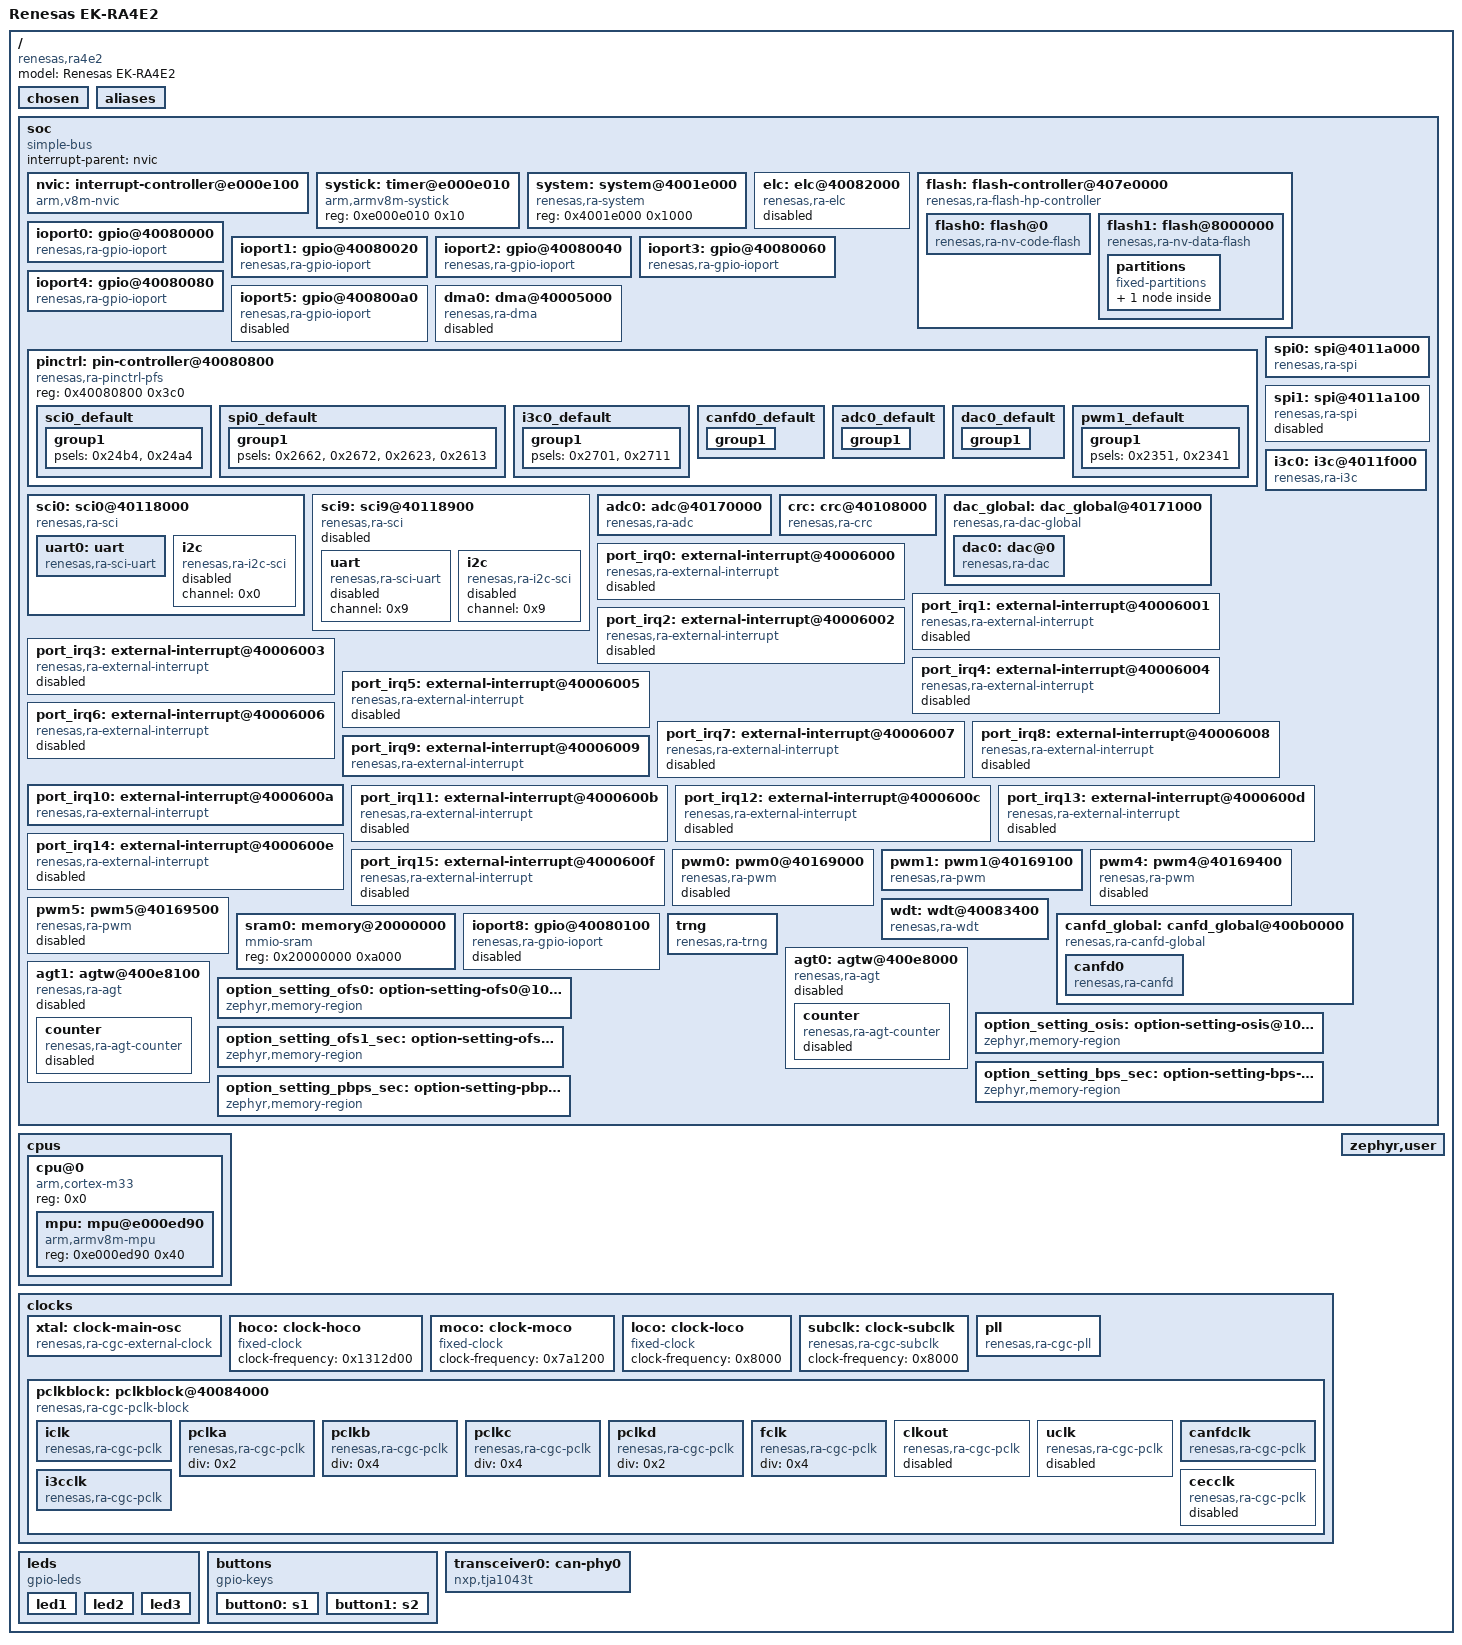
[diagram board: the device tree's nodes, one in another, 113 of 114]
/dts-v1/;

/* node '/' defined in zephyr/dts/common/skeleton.dtsi:9 */
/ {
	#address-cells = < 0x1 >;     /* in zephyr/dts/common/skeleton.dtsi:10 */
	#size-cells = < 0x1 >;        /* in zephyr/dts/common/skeleton.dtsi:11 */
	model = "Renesas EK-RA4E2";   /* in zephyr/boards/renesas/ek_ra4e2/ek_ra4e2.dts:15 */
	compatible = "renesas,ra4e2",
	             "renesas,ra";    /* in zephyr/boards/renesas/ek_ra4e2/ek_ra4e2.dts:16 */

	/* node '/chosen' defined in zephyr/dts/common/skeleton.dtsi:13 */
	chosen {
		zephyr,sram = &sram0;              /* in zephyr/boards/renesas/ek_ra4e2/ek_ra4e2.dts:19 */
		zephyr,flash-controller = &flash1; /* in zephyr/boards/renesas/ek_ra4e2/ek_ra4e2.dts:20 */
		zephyr,flash = &flash0;            /* in zephyr/boards/renesas/ek_ra4e2/ek_ra4e2.dts:21 */
		zephyr,console = &uart0;           /* in zephyr/boards/renesas/ek_ra4e2/ek_ra4e2.dts:22 */
		zephyr,shell-uart = &uart0;        /* in zephyr/boards/renesas/ek_ra4e2/ek_ra4e2.dts:23 */
		zephyr,canbus = &canfd0;           /* in zephyr/boards/renesas/ek_ra4e2/ek_ra4e2.dts:24 */
		zephyr,entropy = &trng;            /* in zephyr/boards/renesas/ek_ra4e2/ek_ra4e2.dts:25 */
		zephyr,crc = &crc;                 /* in zephyr/boards/renesas/ek_ra4e2/ek_ra4e2.dts:26 */
	};

	/* node '/aliases' defined in zephyr/dts/common/skeleton.dtsi:15 */
	aliases {
		led0 = &led1;     /* in zephyr/boards/renesas/ek_ra4e2/ek_ra4e2.dts:65 */
		sw0 = &button0;   /* in zephyr/boards/renesas/ek_ra4e2/ek_ra4e2.dts:66 */
		sw1 = &button1;   /* in zephyr/boards/renesas/ek_ra4e2/ek_ra4e2.dts:67 */
		watchdog0 = &wdt; /* in zephyr/boards/renesas/ek_ra4e2/ek_ra4e2.dts:68 */
	};

	/* node '/soc' defined in zephyr/dts/arm/armv8-m.dtsi:6 */
	soc {
		#address-cells = < 0x1 >;     /* in zephyr/dts/arm/armv8-m.dtsi:7 */
		#size-cells = < 0x1 >;        /* in zephyr/dts/arm/armv8-m.dtsi:8 */
		compatible = "simple-bus";    /* in zephyr/dts/arm/armv8-m.dtsi:9 */
		ranges;                       /* in zephyr/dts/arm/armv8-m.dtsi:11 */
		interrupt-parent = < &nvic >; /* in zephyr/dts/arm/renesas/ra/ra4/ra4-cm33-common.dtsi:33 */

		/* node '/soc/interrupt-controller@e000e100' defined in zephyr/dts/arm/armv8-m.dtsi:13 */
		nvic: interrupt-controller@e000e100 {
			#address-cells = < 0x1 >;            /* in zephyr/dts/arm/armv8-m.dtsi:14 */
			compatible = "arm,v8m-nvic";         /* in zephyr/dts/arm/armv8-m.dtsi:15 */
			reg = < 0xe000e100 0xc00 >;          /* in zephyr/dts/arm/armv8-m.dtsi:16 */
			interrupt-controller;                /* in zephyr/dts/arm/armv8-m.dtsi:17 */
			#interrupt-cells = < 0x2 >;          /* in zephyr/dts/arm/armv8-m.dtsi:18 */
			arm,num-irq-priority-bits = < 0x4 >; /* in zephyr/dts/arm/renesas/ra/ra4/ra4-cm33-common.dtsi:579 */
			phandle = < 0x1 >;                   /* in zephyr/dts/arm/renesas/ra/ra4/ra4-cm33-common.dtsi:33 */
		};

		/* node '/soc/timer@e000e010' defined in zephyr/dts/arm/armv8-m.dtsi:21 */
		systick: timer@e000e010 {
			compatible = "arm,armv8m-systick"; /* in zephyr/dts/arm/armv8-m.dtsi:22 */
			reg = < 0xe000e010 0x10 >;         /* in zephyr/dts/arm/armv8-m.dtsi:23 */
		};

		/* node '/soc/system@4001e000' defined in zephyr/dts/arm/renesas/ra/ra4/ra4-cm33-common.dtsi:35 */
		system: system@4001e000 {
			compatible = "renesas,ra-system"; /* in zephyr/dts/arm/renesas/ra/ra4/ra4-cm33-common.dtsi:36 */
			reg = < 0x4001e000 0x1000 >;      /* in zephyr/dts/arm/renesas/ra/ra4/ra4-cm33-common.dtsi:37 */
			status = "okay";                  /* in zephyr/dts/arm/renesas/ra/ra4/ra4-cm33-common.dtsi:38 */
		};

		/* node '/soc/elc@40082000' defined in zephyr/dts/arm/renesas/ra/ra4/ra4-cm33-common.dtsi:41 */
		elc: elc@40082000 {
			compatible = "renesas,ra-elc"; /* in zephyr/dts/arm/renesas/ra/ra4/ra4-cm33-common.dtsi:42 */
			reg = < 0x40082000 0x70 >;     /* in zephyr/dts/arm/renesas/ra/ra4/ra4-cm33-common.dtsi:43 */
			#renesas-elc-cells = < 0x2 >;  /* in zephyr/dts/arm/renesas/ra/ra4/ra4-cm33-common.dtsi:44 */
			clocks = < &pclkb 0x2 0xe >;   /* in zephyr/dts/arm/renesas/ra/ra4/ra4-cm33-common.dtsi:45 */
			status = "disabled";           /* in zephyr/dts/arm/renesas/ra/ra4/ra4-cm33-common.dtsi:46 */
		};

		/* node '/soc/flash-controller@407e0000' defined in zephyr/dts/arm/renesas/ra/ra4/ra4-cm33-common.dtsi:49 */
		flash: flash-controller@407e0000 {
			compatible = "renesas,ra-flash-hp-controller"; /* in zephyr/dts/arm/renesas/ra/ra4/ra4-cm33-common.dtsi:50 */
			reg = < 0x407e0000 0x10000 >;                  /* in zephyr/dts/arm/renesas/ra/ra4/ra4-cm33-common.dtsi:51 */
			#address-cells = < 0x1 >;                      /* in zephyr/dts/arm/renesas/ra/ra4/ra4-cm33-common.dtsi:52 */
			#size-cells = < 0x1 >;                         /* in zephyr/dts/arm/renesas/ra/ra4/ra4-cm33-common.dtsi:53 */
			interrupts = < 0x31 0x1 >,
			             < 0x32 0x1 >;                     /* in zephyr/dts/arm/renesas/ra/ra4/ra4-cm33-common.dtsi:54 */
			interrupt-names = "frdyi",
			                  "fiferr";                    /* in zephyr/dts/arm/renesas/ra/ra4/ra4-cm33-common.dtsi:55 */
			flash-hardware-version = < 0x28 >;             /* in zephyr/dts/arm/renesas/ra/ra4/r7fa4e2b93cfm.dtsi:43 */
			#erase-block-cells = < 0x2 >;                  /* in zephyr/dts/arm/renesas/ra/ra4/r7fa4e2b93cfm.dtsi:44 */
			phandle = < 0x3 >;                             /* in zephyr/dts/arm/renesas/ra/ra4/r7fa4e2b93cfm.dtsi:51 */

			/* node '/soc/flash-controller@407e0000/flash@0' defined in zephyr/dts/arm/renesas/ra/ra4/r7fa4e2b93cfm.dtsi:46 */
			flash0: flash@0 {
				compatible = "renesas,ra-nv-code-flash"; /* in zephyr/dts/arm/renesas/ra/ra4/r7fa4e2b93cfm.dtsi:47 */
				reg = < 0x0 0x20000 >;                   /* in zephyr/dts/arm/renesas/ra/ra4/r7fa4e2b93cfm.dtsi:48 */
				write-block-size = < 0x80 >;             /* in zephyr/dts/arm/renesas/ra/ra4/r7fa4e2b93cfm.dtsi:49 */
				erase-block-size = < 0x8000 >;           /* in zephyr/dts/arm/renesas/ra/ra4/r7fa4e2b93cfm.dtsi:50 */
				erase-blocks = < &flash 0x8 0x2000 >,
				               < &flash 0x2 0x8000 >;    /* in zephyr/dts/arm/renesas/ra/ra4/r7fa4e2b93cfm.dtsi:51 */
				programming-enable;                      /* in zephyr/dts/arm/renesas/ra/ra4/r7fa4e2b93cfm.dtsi:52 */
			};

			/* node '/soc/flash-controller@407e0000/flash@8000000' defined in zephyr/dts/arm/renesas/ra/ra4/r7fa4e2b93cfm.dtsi:55 */
			flash1: flash@8000000 {
				compatible = "renesas,ra-nv-data-flash"; /* in zephyr/dts/arm/renesas/ra/ra4/r7fa4e2b93cfm.dtsi:56 */
				reg = < 0x8000000 0x1000 >;              /* in zephyr/dts/arm/renesas/ra/ra4/r7fa4e2b93cfm.dtsi:57 */
				write-block-size = < 0x4 >;              /* in zephyr/dts/arm/renesas/ra/ra4/r7fa4e2b93cfm.dtsi:58 */
				erase-block-size = < 0x40 >;             /* in zephyr/dts/arm/renesas/ra/ra4/r7fa4e2b93cfm.dtsi:59 */
				programming-enable;                      /* in zephyr/dts/arm/renesas/ra/ra4/r7fa4e2b93cfm.dtsi:60 */
				erase-value-undefined;                   /* in zephyr/dts/arm/renesas/ra/ra4/r7fa4e2b93cfm.dtsi:61 */

				/* node '/soc/flash-controller@407e0000/flash@8000000/partitions' defined in zephyr/boards/renesas/ek_ra4e2/ek_ra4e2.dts:209 */
				partitions {
					compatible = "fixed-partitions"; /* in zephyr/boards/renesas/ek_ra4e2/ek_ra4e2.dts:210 */
					#address-cells = < 0x1 >;        /* in zephyr/boards/renesas/ek_ra4e2/ek_ra4e2.dts:211 */
					#size-cells = < 0x1 >;           /* in zephyr/boards/renesas/ek_ra4e2/ek_ra4e2.dts:212 */

					/* node '/soc/flash-controller@407e0000/flash@8000000/partitions/partition@0' defined in zephyr/boards/renesas/ek_ra4e2/ek_ra4e2.dts:214 */
					storage_partition: partition@0 {
						label = "storage";    /* in zephyr/boards/renesas/ek_ra4e2/ek_ra4e2.dts:215 */
						reg = < 0x0 0x1000 >; /* in zephyr/boards/renesas/ek_ra4e2/ek_ra4e2.dts:216 */
					};
				};
			};
		};

		/* node '/soc/gpio@40080000' defined in zephyr/dts/arm/renesas/ra/ra4/ra4-cm33-common.dtsi:58 */
		ioport0: gpio@40080000 {
			compatible = "renesas,ra-gpio-ioport";                                                                       /* in zephyr/dts/arm/renesas/ra/ra4/ra4-cm33-common.dtsi:59 */
			reg = < 0x40080000 0x20 >;                                                                                   /* in zephyr/dts/arm/renesas/ra/ra4/ra4-cm33-common.dtsi:60 */
			port = < 0x0 >;                                                                                              /* in zephyr/dts/arm/renesas/ra/ra4/ra4-cm33-common.dtsi:61 */
			gpio-controller;                                                                                             /* in zephyr/dts/arm/renesas/ra/ra4/ra4-cm33-common.dtsi:62 */
			#gpio-cells = < 0x2 >;                                                                                       /* in zephyr/dts/arm/renesas/ra/ra4/ra4-cm33-common.dtsi:63 */
			ngpios = < 0x10 >;                                                                                           /* in zephyr/dts/arm/renesas/ra/ra4/ra4-cm33-common.dtsi:64 */
			port-irqs = < &port_irq6 &port_irq7 &port_irq8 &port_irq9 &port_irq10 &port_irq11 &port_irq12 &port_irq13 >; /* in zephyr/dts/arm/renesas/ra/ra4/r7fa4e2b93cfm.dtsi:295 */
			port-irq-names = "port-irq6",
			                 "port-irq7",
			                 "port-irq8",
			                 "port-irq9",
			                 "port-irq10",
			                 "port-irq11",
			                 "port-irq12",
			                 "port-irq13";                                                                               /* in zephyr/dts/arm/renesas/ra/ra4/r7fa4e2b93cfm.dtsi:298 */
			port-irq6-pins = < 0x0 >;                                                                                    /* in zephyr/dts/arm/renesas/ra/ra4/r7fa4e2b93cfm.dtsi:306 */
			port-irq7-pins = < 0x1 >;                                                                                    /* in zephyr/dts/arm/renesas/ra/ra4/r7fa4e2b93cfm.dtsi:307 */
			port-irq8-pins = < 0x2 >;                                                                                    /* in zephyr/dts/arm/renesas/ra/ra4/r7fa4e2b93cfm.dtsi:308 */
			port-irq9-pins = < 0x4 >;                                                                                    /* in zephyr/dts/arm/renesas/ra/ra4/r7fa4e2b93cfm.dtsi:309 */
			port-irq10-pins = < 0x5 >;                                                                                   /* in zephyr/dts/arm/renesas/ra/ra4/r7fa4e2b93cfm.dtsi:310 */
			port-irq11-pins = < 0x6 >;                                                                                   /* in zephyr/dts/arm/renesas/ra/ra4/r7fa4e2b93cfm.dtsi:311 */
			port-irq12-pins = < 0x8 >;                                                                                   /* in zephyr/dts/arm/renesas/ra/ra4/r7fa4e2b93cfm.dtsi:312 */
			port-irq13-pins = < 0xf >;                                                                                   /* in zephyr/dts/arm/renesas/ra/ra4/r7fa4e2b93cfm.dtsi:313 */
			status = "okay";                                                                                             /* in zephyr/boards/renesas/ek_ra4e2/ek_ra4e2.dts:114 */
			phandle = < 0x24 >;                                                                                          /* in zephyr/boards/renesas/ek_ra4e2/ek_ra4e2.dts:52 */
		};

		/* node '/soc/gpio@40080020' defined in zephyr/dts/arm/renesas/ra/ra4/ra4-cm33-common.dtsi:68 */
		ioport1: gpio@40080020 {
			compatible = "renesas,ra-gpio-ioport";                                  /* in zephyr/dts/arm/renesas/ra/ra4/ra4-cm33-common.dtsi:69 */
			reg = < 0x40080020 0x20 >;                                              /* in zephyr/dts/arm/renesas/ra/ra4/ra4-cm33-common.dtsi:70 */
			port = < 0x1 >;                                                         /* in zephyr/dts/arm/renesas/ra/ra4/ra4-cm33-common.dtsi:71 */
			gpio-controller;                                                        /* in zephyr/dts/arm/renesas/ra/ra4/ra4-cm33-common.dtsi:72 */
			#gpio-cells = < 0x2 >;                                                  /* in zephyr/dts/arm/renesas/ra/ra4/ra4-cm33-common.dtsi:73 */
			ngpios = < 0x10 >;                                                      /* in zephyr/dts/arm/renesas/ra/ra4/ra4-cm33-common.dtsi:74 */
			port-irqs = < &port_irq0 &port_irq1 &port_irq2 &port_irq3 &port_irq4 >; /* in zephyr/dts/arm/renesas/ra/ra4/r7fa4e2b93cfm.dtsi:317 */
			port-irq-names = "port-irq0",
			                 "port-irq1",
			                 "port-irq2",
			                 "port-irq3",
			                 "port-irq4";                                           /* in zephyr/dts/arm/renesas/ra/ra4/r7fa4e2b93cfm.dtsi:319 */
			port-irq0-pins = < 0x5 >;                                               /* in zephyr/dts/arm/renesas/ra/ra4/r7fa4e2b93cfm.dtsi:324 */
			port-irq1-pins = < 0x1 0x4 >;                                           /* in zephyr/dts/arm/renesas/ra/ra4/r7fa4e2b93cfm.dtsi:325 */
			port-irq2-pins = < 0x0 >;                                               /* in zephyr/dts/arm/renesas/ra/ra4/r7fa4e2b93cfm.dtsi:326 */
			port-irq3-pins = < 0xa >;                                               /* in zephyr/dts/arm/renesas/ra/ra4/r7fa4e2b93cfm.dtsi:327 */
			port-irq4-pins = < 0xb >;                                               /* in zephyr/dts/arm/renesas/ra/ra4/r7fa4e2b93cfm.dtsi:328 */
			status = "okay";                                                        /* in zephyr/boards/renesas/ek_ra4e2/ek_ra4e2.dts:118 */
			phandle = < 0x23 >;                                                     /* in zephyr/boards/renesas/ek_ra4e2/ek_ra4e2.dts:38 */
		};

		/* node '/soc/gpio@40080040' defined in zephyr/dts/arm/renesas/ra/ra4/ra4-cm33-common.dtsi:78 */
		ioport2: gpio@40080040 {
			compatible = "renesas,ra-gpio-ioport";                       /* in zephyr/dts/arm/renesas/ra/ra4/ra4-cm33-common.dtsi:79 */
			reg = < 0x40080040 0x20 >;                                   /* in zephyr/dts/arm/renesas/ra/ra4/ra4-cm33-common.dtsi:80 */
			port = < 0x2 >;                                              /* in zephyr/dts/arm/renesas/ra/ra4/ra4-cm33-common.dtsi:81 */
			gpio-controller;                                             /* in zephyr/dts/arm/renesas/ra/ra4/ra4-cm33-common.dtsi:82 */
			#gpio-cells = < 0x2 >;                                       /* in zephyr/dts/arm/renesas/ra/ra4/ra4-cm33-common.dtsi:83 */
			ngpios = < 0x10 >;                                           /* in zephyr/dts/arm/renesas/ra/ra4/ra4-cm33-common.dtsi:84 */
			port-irqs = < &port_irq0 &port_irq1 &port_irq2 &port_irq3 >; /* in zephyr/dts/arm/renesas/ra/ra4/r7fa4e2b93cfm.dtsi:332 */
			port-irq-names = "port-irq0",
			                 "port-irq1",
			                 "port-irq2",
			                 "port-irq3";                                /* in zephyr/dts/arm/renesas/ra/ra4/r7fa4e2b93cfm.dtsi:334 */
			port-irq0-pins = < 0x6 >;                                    /* in zephyr/dts/arm/renesas/ra/ra4/r7fa4e2b93cfm.dtsi:338 */
			port-irq1-pins = < 0x5 >;                                    /* in zephyr/dts/arm/renesas/ra/ra4/r7fa4e2b93cfm.dtsi:339 */
			port-irq2-pins = < 0xd >;                                    /* in zephyr/dts/arm/renesas/ra/ra4/r7fa4e2b93cfm.dtsi:340 */
			port-irq3-pins = < 0xc >;                                    /* in zephyr/dts/arm/renesas/ra/ra4/r7fa4e2b93cfm.dtsi:341 */
			status = "okay";                                             /* in zephyr/boards/renesas/ek_ra4e2/ek_ra4e2.dts:122 */
			phandle = < 0x22 >;                                          /* in zephyr/boards/renesas/ek_ra4e2/ek_ra4e2.dts:33 */
		};

		/* node '/soc/gpio@40080060' defined in zephyr/dts/arm/renesas/ra/ra4/ra4-cm33-common.dtsi:88 */
		ioport3: gpio@40080060 {
			compatible = "renesas,ra-gpio-ioport";            /* in zephyr/dts/arm/renesas/ra/ra4/ra4-cm33-common.dtsi:89 */
			reg = < 0x40080060 0x20 >;                        /* in zephyr/dts/arm/renesas/ra/ra4/ra4-cm33-common.dtsi:90 */
			port = < 0x3 >;                                   /* in zephyr/dts/arm/renesas/ra/ra4/ra4-cm33-common.dtsi:91 */
			gpio-controller;                                  /* in zephyr/dts/arm/renesas/ra/ra4/ra4-cm33-common.dtsi:92 */
			#gpio-cells = < 0x2 >;                            /* in zephyr/dts/arm/renesas/ra/ra4/ra4-cm33-common.dtsi:93 */
			ngpios = < 0x10 >;                                /* in zephyr/dts/arm/renesas/ra/ra4/ra4-cm33-common.dtsi:94 */
			port-irqs = < &port_irq5 &port_irq6 &port_irq9 >; /* in zephyr/dts/arm/renesas/ra/ra4/r7fa4e2b93cfm.dtsi:345 */
			port-irq-names = "port-irq5",
			                 "port-irq6",
			                 "port-irq9";                     /* in zephyr/dts/arm/renesas/ra/ra4/r7fa4e2b93cfm.dtsi:346 */
			port-irq5-pins = < 0x2 >;                         /* in zephyr/dts/arm/renesas/ra/ra4/r7fa4e2b93cfm.dtsi:349 */
			port-irq6-pins = < 0x1 >;                         /* in zephyr/dts/arm/renesas/ra/ra4/r7fa4e2b93cfm.dtsi:350 */
			port-irq9-pins = < 0x4 >;                         /* in zephyr/dts/arm/renesas/ra/ra4/r7fa4e2b93cfm.dtsi:351 */
			status = "okay";                                  /* in zephyr/boards/renesas/ek_ra4e2/ek_ra4e2.dts:182 */
			phandle = < 0x25 >;                               /* in zephyr/boards/renesas/ek_ra4e2/ek_ra4e2.dts:58 */
		};

		/* node '/soc/gpio@40080080' defined in zephyr/dts/arm/renesas/ra/ra4/ra4-cm33-common.dtsi:98 */
		ioport4: gpio@40080080 {
			compatible = "renesas,ra-gpio-ioport";                                              /* in zephyr/dts/arm/renesas/ra/ra4/ra4-cm33-common.dtsi:99 */
			reg = < 0x40080080 0x20 >;                                                          /* in zephyr/dts/arm/renesas/ra/ra4/ra4-cm33-common.dtsi:100 */
			port = < 0x4 >;                                                                     /* in zephyr/dts/arm/renesas/ra/ra4/ra4-cm33-common.dtsi:101 */
			gpio-controller;                                                                    /* in zephyr/dts/arm/renesas/ra/ra4/ra4-cm33-common.dtsi:102 */
			#gpio-cells = < 0x2 >;                                                              /* in zephyr/dts/arm/renesas/ra/ra4/ra4-cm33-common.dtsi:103 */
			ngpios = < 0x10 >;                                                                  /* in zephyr/dts/arm/renesas/ra/ra4/ra4-cm33-common.dtsi:104 */
			port-irqs = < &port_irq0 &port_irq4 &port_irq5 &port_irq6 &port_irq7 &port_irq14 >; /* in zephyr/dts/arm/renesas/ra/ra4/r7fa4e2b93cfm.dtsi:355 */
			port-irq-names = "port-irq0",
			                 "port-irq4",
			                 "port-irq5",
			                 "port-irq6",
			                 "port-irq7",
			                 "port-irq14";                                                      /* in zephyr/dts/arm/renesas/ra/ra4/r7fa4e2b93cfm.dtsi:357 */
			port-irq0-pins = < 0x0 >;                                                           /* in zephyr/dts/arm/renesas/ra/ra4/r7fa4e2b93cfm.dtsi:363 */
			port-irq4-pins = < 0x2 0xb >;                                                       /* in zephyr/dts/arm/renesas/ra/ra4/r7fa4e2b93cfm.dtsi:364 */
			port-irq5-pins = < 0x1 0xa >;                                                       /* in zephyr/dts/arm/renesas/ra/ra4/r7fa4e2b93cfm.dtsi:365 */
			port-irq6-pins = < 0x9 >;                                                           /* in zephyr/dts/arm/renesas/ra/ra4/r7fa4e2b93cfm.dtsi:366 */
			port-irq7-pins = < 0x8 >;                                                           /* in zephyr/dts/arm/renesas/ra/ra4/r7fa4e2b93cfm.dtsi:367 */
			port-irq14-pins = < 0x3 >;                                                          /* in zephyr/dts/arm/renesas/ra/ra4/r7fa4e2b93cfm.dtsi:368 */
			status = "okay";                                                                    /* in zephyr/boards/renesas/ek_ra4e2/ek_ra4e2.dts:142 */
			phandle = < 0x26 >;                                                                 /* in zephyr/boards/renesas/ek_ra4e2/ek_ra4e2.dts:73 */
		};

		/* node '/soc/gpio@400800a0' defined in zephyr/dts/arm/renesas/ra/ra4/ra4-cm33-common.dtsi:109 */
		ioport5: gpio@400800a0 {
			compatible = "renesas,ra-gpio-ioport"; /* in zephyr/dts/arm/renesas/ra/ra4/ra4-cm33-common.dtsi:110 */
			reg = < 0x400800a0 0x20 >;             /* in zephyr/dts/arm/renesas/ra/ra4/ra4-cm33-common.dtsi:111 */
			port = < 0x5 >;                        /* in zephyr/dts/arm/renesas/ra/ra4/ra4-cm33-common.dtsi:112 */
			gpio-controller;                       /* in zephyr/dts/arm/renesas/ra/ra4/ra4-cm33-common.dtsi:113 */
			#gpio-cells = < 0x2 >;                 /* in zephyr/dts/arm/renesas/ra/ra4/ra4-cm33-common.dtsi:114 */
			ngpios = < 0x10 >;                     /* in zephyr/dts/arm/renesas/ra/ra4/ra4-cm33-common.dtsi:115 */
			status = "disabled";                   /* in zephyr/dts/arm/renesas/ra/ra4/ra4-cm33-common.dtsi:116 */
		};

		/* node '/soc/dma@40005000' defined in zephyr/dts/arm/renesas/ra/ra4/ra4-cm33-common.dtsi:119 */
		dma0: dma@40005000 {
			compatible = "renesas,ra-dma"; /* in zephyr/dts/arm/renesas/ra/ra4/ra4-cm33-common.dtsi:120 */
			reg = < 0x40005000 0x200 >,
			      < 0x40005200 0xa0 >;     /* in zephyr/dts/arm/renesas/ra/ra4/ra4-cm33-common.dtsi:121 */
			reg-names = "channel",
			            "common";          /* in zephyr/dts/arm/renesas/ra/ra4/ra4-cm33-common.dtsi:122 */
			clocks = < &iclk 0x0 0x16 >;   /* in zephyr/dts/arm/renesas/ra/ra4/ra4-cm33-common.dtsi:123 */
			dma-channels = < 0x8 >;        /* in zephyr/dts/arm/renesas/ra/ra4/ra4-cm33-common.dtsi:124 */
			#dma-cells = < 0x2 >;          /* in zephyr/dts/arm/renesas/ra/ra4/ra4-cm33-common.dtsi:125 */
			status = "disabled";           /* in zephyr/dts/arm/renesas/ra/ra4/ra4-cm33-common.dtsi:126 */
		};

		/* node '/soc/pin-controller@40080800' defined in zephyr/dts/arm/renesas/ra/ra4/ra4-cm33-common.dtsi:129 */
		pinctrl: pin-controller@40080800 {
			compatible = "renesas,ra-pinctrl-pfs"; /* in zephyr/dts/arm/renesas/ra/ra4/ra4-cm33-common.dtsi:130 */
			reg = < 0x40080800 0x3c0 >;            /* in zephyr/dts/arm/renesas/ra/ra4/ra4-cm33-common.dtsi:131 */
			status = "okay";                       /* in zephyr/dts/arm/renesas/ra/ra4/ra4-cm33-common.dtsi:132 */

			/* node '/soc/pin-controller@40080800/sci0_default' defined in zephyr/boards/renesas/ek_ra4e2/ek_ra4e2-pinctrl.dtsi:7 */
			sci0_default: sci0_default {
				phandle = < 0x15 >; /* in zephyr/boards/renesas/ek_ra4e2/ek_ra4e2.dts:103 */

				/* node '/soc/pin-controller@40080800/sci0_default/group1' defined in zephyr/boards/renesas/ek_ra4e2/ek_ra4e2-pinctrl.dtsi:8 */
				group1 {
					psels = < 0x24b4 >,
					        < 0x24a4 >; /* in zephyr/boards/renesas/ek_ra4e2/ek_ra4e2-pinctrl.dtsi:10 */
				};
			};

			/* node '/soc/pin-controller@40080800/spi0_default' defined in zephyr/boards/renesas/ek_ra4e2/ek_ra4e2-pinctrl.dtsi:15 */
			spi0_default: spi0_default {
				phandle = < 0x16 >; /* in zephyr/boards/renesas/ek_ra4e2/ek_ra4e2.dts:126 */

				/* node '/soc/pin-controller@40080800/spi0_default/group1' defined in zephyr/boards/renesas/ek_ra4e2/ek_ra4e2-pinctrl.dtsi:16 */
				group1 {
					psels = < 0x2662 >,
					        < 0x2672 >,
					        < 0x2623 >,
					        < 0x2613 >; /* in zephyr/boards/renesas/ek_ra4e2/ek_ra4e2-pinctrl.dtsi:18 */
				};
			};

			/* node '/soc/pin-controller@40080800/i3c0_default' defined in zephyr/boards/renesas/ek_ra4e2/ek_ra4e2-pinctrl.dtsi:25 */
			i3c0_default: i3c0_default {
				phandle = < 0x18 >; /* in zephyr/boards/renesas/ek_ra4e2/ek_ra4e2.dts:134 */

				/* node '/soc/pin-controller@40080800/i3c0_default/group1' defined in zephyr/boards/renesas/ek_ra4e2/ek_ra4e2-pinctrl.dtsi:26 */
				group1 {
					psels = < 0x2701 >,
					        < 0x2711 >; /* in zephyr/boards/renesas/ek_ra4e2/ek_ra4e2-pinctrl.dtsi:28 */
				};
			};

			/* node '/soc/pin-controller@40080800/canfd0_default' defined in zephyr/boards/renesas/ek_ra4e2/ek_ra4e2-pinctrl.dtsi:33 */
			canfd0_default: canfd0_default {
				phandle = < 0x1e >; /* in zephyr/boards/renesas/ek_ra4e2/ek_ra4e2.dts:161 */

				/* node '/soc/pin-controller@40080800/canfd0_default/group1' defined in zephyr/boards/renesas/ek_ra4e2/ek_ra4e2-pinctrl.dtsi:34 */
				group1 {
					psels = < 0x3024 >,
					        < 0x3014 >;      /* in zephyr/boards/renesas/ek_ra4e2/ek_ra4e2-pinctrl.dtsi:36 */
					drive-strength = "high"; /* in zephyr/boards/renesas/ek_ra4e2/ek_ra4e2-pinctrl.dtsi:38 */
				};
			};

			/* node '/soc/pin-controller@40080800/adc0_default' defined in zephyr/boards/renesas/ek_ra4e2/ek_ra4e2-pinctrl.dtsi:42 */
			adc0_default: adc0_default {
				phandle = < 0x19 >; /* in zephyr/boards/renesas/ek_ra4e2/ek_ra4e2.dts:171 */

				/* node '/soc/pin-controller@40080800/adc0_default/group1' defined in zephyr/boards/renesas/ek_ra4e2/ek_ra4e2-pinctrl.dtsi:43 */
				group1 {
					psels = < 0x2000 >;    /* in zephyr/boards/renesas/ek_ra4e2/ek_ra4e2-pinctrl.dtsi:45 */
					renesas,analog-enable; /* in zephyr/boards/renesas/ek_ra4e2/ek_ra4e2-pinctrl.dtsi:46 */
				};
			};

			/* node '/soc/pin-controller@40080800/dac0_default' defined in zephyr/boards/renesas/ek_ra4e2/ek_ra4e2-pinctrl.dtsi:50 */
			dac0_default: dac0_default {
				phandle = < 0x1a >; /* in zephyr/boards/renesas/ek_ra4e2/ek_ra4e2.dts:176 */

				/* node '/soc/pin-controller@40080800/dac0_default/group1' defined in zephyr/boards/renesas/ek_ra4e2/ek_ra4e2-pinctrl.dtsi:51 */
				group1 {
					psels = < 0x20e0 >;    /* in zephyr/boards/renesas/ek_ra4e2/ek_ra4e2-pinctrl.dtsi:53 */
					renesas,analog-enable; /* in zephyr/boards/renesas/ek_ra4e2/ek_ra4e2-pinctrl.dtsi:54 */
				};
			};

			/* node '/soc/pin-controller@40080800/pwm1_default' defined in zephyr/boards/renesas/ek_ra4e2/ek_ra4e2-pinctrl.dtsi:58 */
			pwm1_default: pwm1_default {
				phandle = < 0x1c >; /* in zephyr/boards/renesas/ek_ra4e2/ek_ra4e2.dts:196 */

				/* node '/soc/pin-controller@40080800/pwm1_default/group1' defined in zephyr/boards/renesas/ek_ra4e2/ek_ra4e2-pinctrl.dtsi:59 */
				group1 {
					psels = < 0x2351 >,
					        < 0x2341 >; /* in zephyr/boards/renesas/ek_ra4e2/ek_ra4e2-pinctrl.dtsi:61 */
				};
			};
		};

		/* node '/soc/sci0@40118000' defined in zephyr/dts/arm/renesas/ra/ra4/ra4-cm33-common.dtsi:135 */
		sci0: sci0@40118000 {
			compatible = "renesas,ra-sci"; /* in zephyr/dts/arm/renesas/ra/ra4/ra4-cm33-common.dtsi:136 */
			interrupts = < 0x0 0x1 >,
			             < 0x1 0x1 >,
			             < 0x2 0x1 >,
			             < 0x3 0x1 >;      /* in zephyr/dts/arm/renesas/ra/ra4/ra4-cm33-common.dtsi:137 */
			interrupt-names = "rxi",
			                  "txi",
			                  "tei",
			                  "eri";       /* in zephyr/dts/arm/renesas/ra/ra4/ra4-cm33-common.dtsi:138 */
			reg = < 0x40118000 0x100 >;    /* in zephyr/dts/arm/renesas/ra/ra4/ra4-cm33-common.dtsi:139 */
			clocks = < &pclka 0x1 0x1f >;  /* in zephyr/dts/arm/renesas/ra/ra4/ra4-cm33-common.dtsi:140 */
			pinctrl-0 = < &sci0_default >; /* in zephyr/boards/renesas/ek_ra4e2/ek_ra4e2.dts:103 */
			pinctrl-names = "default";     /* in zephyr/boards/renesas/ek_ra4e2/ek_ra4e2.dts:104 */
			status = "okay";               /* in zephyr/boards/renesas/ek_ra4e2/ek_ra4e2.dts:105 */

			/* node '/soc/sci0@40118000/uart' defined in zephyr/dts/arm/renesas/ra/ra4/ra4-cm33-common.dtsi:143 */
			uart0: uart {
				compatible = "renesas,ra-sci-uart"; /* in zephyr/dts/arm/renesas/ra/ra4/ra4-cm33-common.dtsi:144 */
				channel = < 0x0 >;                  /* in zephyr/dts/arm/renesas/ra/ra4/ra4-cm33-common.dtsi:145 */
				current-speed = < 0x1c200 >;        /* in zephyr/boards/renesas/ek_ra4e2/ek_ra4e2.dts:108 */
				status = "okay";                    /* in zephyr/boards/renesas/ek_ra4e2/ek_ra4e2.dts:109 */
			};

			/* node '/soc/sci0@40118000/i2c' defined in zephyr/dts/arm/renesas/ra/ra4/ra4-cm33-common.dtsi:149 */
			i2c {
				compatible = "renesas,ra-i2c-sci"; /* in zephyr/dts/arm/renesas/ra/ra4/ra4-cm33-common.dtsi:150 */
				#address-cells = < 0x1 >;          /* in zephyr/dts/arm/renesas/ra/ra4/ra4-cm33-common.dtsi:151 */
				#size-cells = < 0x0 >;             /* in zephyr/dts/arm/renesas/ra/ra4/ra4-cm33-common.dtsi:152 */
				channel = < 0x0 >;                 /* in zephyr/dts/arm/renesas/ra/ra4/ra4-cm33-common.dtsi:153 */
				status = "disabled";               /* in zephyr/dts/arm/renesas/ra/ra4/ra4-cm33-common.dtsi:154 */
			};
		};

		/* node '/soc/sci9@40118900' defined in zephyr/dts/arm/renesas/ra/ra4/ra4-cm33-common.dtsi:158 */
		sci9: sci9@40118900 {
			compatible = "renesas,ra-sci"; /* in zephyr/dts/arm/renesas/ra/ra4/ra4-cm33-common.dtsi:159 */
			interrupts = < 0x18 0x1 >,
			             < 0x19 0x1 >,
			             < 0x1a 0x1 >,
			             < 0x1b 0x1 >;     /* in zephyr/dts/arm/renesas/ra/ra4/ra4-cm33-common.dtsi:160 */
			interrupt-names = "rxi",
			                  "txi",
			                  "tei",
			                  "eri";       /* in zephyr/dts/arm/renesas/ra/ra4/ra4-cm33-common.dtsi:161 */
			reg = < 0x40118900 0x100 >;    /* in zephyr/dts/arm/renesas/ra/ra4/ra4-cm33-common.dtsi:162 */
			clocks = < &pclka 0x1 0x16 >;  /* in zephyr/dts/arm/renesas/ra/ra4/ra4-cm33-common.dtsi:163 */
			status = "disabled";           /* in zephyr/dts/arm/renesas/ra/ra4/ra4-cm33-common.dtsi:164 */

			/* node '/soc/sci9@40118900/uart' defined in zephyr/dts/arm/renesas/ra/ra4/ra4-cm33-common.dtsi:166 */
			uart {
				compatible = "renesas,ra-sci-uart"; /* in zephyr/dts/arm/renesas/ra/ra4/ra4-cm33-common.dtsi:167 */
				channel = < 0x9 >;                  /* in zephyr/dts/arm/renesas/ra/ra4/ra4-cm33-common.dtsi:168 */
				status = "disabled";                /* in zephyr/dts/arm/renesas/ra/ra4/ra4-cm33-common.dtsi:169 */
			};

			/* node '/soc/sci9@40118900/i2c' defined in zephyr/dts/arm/renesas/ra/ra4/ra4-cm33-common.dtsi:172 */
			i2c {
				compatible = "renesas,ra-i2c-sci"; /* in zephyr/dts/arm/renesas/ra/ra4/ra4-cm33-common.dtsi:173 */
				#address-cells = < 0x1 >;          /* in zephyr/dts/arm/renesas/ra/ra4/ra4-cm33-common.dtsi:174 */
				#size-cells = < 0x0 >;             /* in zephyr/dts/arm/renesas/ra/ra4/ra4-cm33-common.dtsi:175 */
				channel = < 0x9 >;                 /* in zephyr/dts/arm/renesas/ra/ra4/ra4-cm33-common.dtsi:176 */
				status = "disabled";               /* in zephyr/dts/arm/renesas/ra/ra4/ra4-cm33-common.dtsi:177 */
			};
		};

		/* node '/soc/spi@4011a000' defined in zephyr/dts/arm/renesas/ra/ra4/ra4-cm33-common.dtsi:181 */
		spi0: spi@4011a000 {
			compatible = "renesas,ra-spi"; /* in zephyr/dts/arm/renesas/ra/ra4/ra4-cm33-common.dtsi:182 */
			#address-cells = < 0x1 >;      /* in zephyr/dts/arm/renesas/ra/ra4/ra4-cm33-common.dtsi:183 */
			#size-cells = < 0x0 >;         /* in zephyr/dts/arm/renesas/ra/ra4/ra4-cm33-common.dtsi:184 */
			channel = < 0x0 >;             /* in zephyr/dts/arm/renesas/ra/ra4/ra4-cm33-common.dtsi:185 */
			interrupts = < 0x1c 0x1 >,
			             < 0x1d 0x1 >,
			             < 0x1e 0x1 >,
			             < 0x1f 0x1 >;     /* in zephyr/dts/arm/renesas/ra/ra4/ra4-cm33-common.dtsi:186 */
			interrupt-names = "rxi",
			                  "txi",
			                  "tei",
			                  "eri";       /* in zephyr/dts/arm/renesas/ra/ra4/ra4-cm33-common.dtsi:187 */
			reg = < 0x4011a000 0x100 >;    /* in zephyr/dts/arm/renesas/ra/ra4/ra4-cm33-common.dtsi:188 */
			pinctrl-0 = < &spi0_default >; /* in zephyr/boards/renesas/ek_ra4e2/ek_ra4e2.dts:126 */
			pinctrl-names = "default";     /* in zephyr/boards/renesas/ek_ra4e2/ek_ra4e2.dts:127 */
			status = "okay";               /* in zephyr/boards/renesas/ek_ra4e2/ek_ra4e2.dts:128 */
		};

		/* node '/soc/spi@4011a100' defined in zephyr/dts/arm/renesas/ra/ra4/ra4-cm33-common.dtsi:192 */
		spi1: spi@4011a100 {
			compatible = "renesas,ra-spi"; /* in zephyr/dts/arm/renesas/ra/ra4/ra4-cm33-common.dtsi:193 */
			#address-cells = < 0x1 >;      /* in zephyr/dts/arm/renesas/ra/ra4/ra4-cm33-common.dtsi:194 */
			#size-cells = < 0x0 >;         /* in zephyr/dts/arm/renesas/ra/ra4/ra4-cm33-common.dtsi:195 */
			channel = < 0x1 >;             /* in zephyr/dts/arm/renesas/ra/ra4/ra4-cm33-common.dtsi:196 */
			reg = < 0x4011a100 0x100 >;    /* in zephyr/dts/arm/renesas/ra/ra4/ra4-cm33-common.dtsi:197 */
			status = "disabled";           /* in zephyr/dts/arm/renesas/ra/ra4/ra4-cm33-common.dtsi:198 */
		};

		/* node '/soc/i3c@4011f000' defined in zephyr/dts/arm/renesas/ra/ra4/ra4-cm33-common.dtsi:201 */
		i3c0: i3c@4011f000 {
			compatible = "renesas,ra-i3c"; /* in zephyr/dts/arm/renesas/ra/ra4/ra4-cm33-common.dtsi:202 */
			#address-cells = < 0x3 >;      /* in zephyr/dts/arm/renesas/ra/ra4/ra4-cm33-common.dtsi:203 */
			#size-cells = < 0x0 >;         /* in zephyr/dts/arm/renesas/ra/ra4/ra4-cm33-common.dtsi:204 */
			reg = < 0x4011f000 0x3e8 >;    /* in zephyr/dts/arm/renesas/ra/ra4/ra4-cm33-common.dtsi:205 */
			channel = < 0x0 >;             /* in zephyr/dts/arm/renesas/ra/ra4/ra4-cm33-common.dtsi:206 */
			clocks = < &pclka 0x1 0x4 >,
			         < &i3cclk 0x0 0x0 >;  /* in zephyr/dts/arm/renesas/ra/ra4/ra4-cm33-common.dtsi:207 */
			clock-names = "pclk",
			              "tclk";          /* in zephyr/dts/arm/renesas/ra/ra4/ra4-cm33-common.dtsi:208 */
			i2c-scl-hz = < 0x61a80 >;      /* in zephyr/boards/renesas/ek_ra4e2/ek_ra4e2.dts:132 */
			i3c-scl-hz = < 0x3d0900 >;     /* in zephyr/boards/renesas/ek_ra4e2/ek_ra4e2.dts:133 */
			pinctrl-0 = < &i3c0_default >; /* in zephyr/boards/renesas/ek_ra4e2/ek_ra4e2.dts:134 */
			pinctrl-names = "default";     /* in zephyr/boards/renesas/ek_ra4e2/ek_ra4e2.dts:135 */
			interrupts = < 0x33 0x1 >,
			             < 0x34 0x1 >,
			             < 0x35 0x1 >,
			             < 0x36 0x1 >,
			             < 0x37 0x1 >,
			             < 0x38 0x1 >;     /* in zephyr/boards/renesas/ek_ra4e2/ek_ra4e2.dts:136 */
			interrupt-names = "resp",
			                  "rx",
			                  "tx",
			                  "rcv",
			                  "ibi",
			                  "eei";       /* in zephyr/boards/renesas/ek_ra4e2/ek_ra4e2.dts:137 */
			status = "okay";               /* in zephyr/boards/renesas/ek_ra4e2/ek_ra4e2.dts:138 */
		};

		/* node '/soc/adc@40170000' defined in zephyr/dts/arm/renesas/ra/ra4/ra4-cm33-common.dtsi:302 */
		adc0: adc@40170000 {
			compatible = "renesas,ra-adc";        /* in zephyr/dts/arm/renesas/ra/ra4/ra4-cm33-common.dtsi:303 */
			interrupts = < 0x26 0x1 >;            /* in zephyr/dts/arm/renesas/ra/ra4/ra4-cm33-common.dtsi:304 */
			interrupt-names = "scanend";          /* in zephyr/dts/arm/renesas/ra/ra4/ra4-cm33-common.dtsi:305 */
			reg = < 0x40170000 0x100 >;           /* in zephyr/dts/arm/renesas/ra/ra4/ra4-cm33-common.dtsi:306 */
			#io-channel-cells = < 0x1 >;          /* in zephyr/dts/arm/renesas/ra/ra4/ra4-cm33-common.dtsi:307 */
			vref-mv = < 0xce4 >;                  /* in zephyr/dts/arm/renesas/ra/ra4/ra4-cm33-common.dtsi:308 */
			channel-available-mask = < 0x139f7 >; /* in zephyr/dts/arm/renesas/ra/ra4/r7fa4e2b93cfm.dtsi:66 */
			status = "okay";                      /* in zephyr/boards/renesas/ek_ra4e2/ek_ra4e2.dts:170 */
			pinctrl-0 = < &adc0_default >;        /* in zephyr/boards/renesas/ek_ra4e2/ek_ra4e2.dts:171 */
			pinctrl-names = "default";            /* in zephyr/boards/renesas/ek_ra4e2/ek_ra4e2.dts:172 */
		};

		/* node '/soc/crc@40108000' defined in zephyr/dts/arm/renesas/ra/ra4/ra4-cm33-common.dtsi:322 */
		crc: crc@40108000 {
			compatible = "renesas,ra-crc"; /* in zephyr/dts/arm/renesas/ra/ra4/ra4-cm33-common.dtsi:323 */
			reg = < 0x40108000 0x1000 >;   /* in zephyr/dts/arm/renesas/ra/ra4/ra4-cm33-common.dtsi:324 */
			clocks = < &pclka 0x2 0x1 >;   /* in zephyr/dts/arm/renesas/ra/ra4/ra4-cm33-common.dtsi:325 */
			status = "okay";               /* in zephyr/boards/renesas/ek_ra4e2/ek_ra4e2.dts:226 */
		};

		/* node '/soc/dac_global@40171000' defined in zephyr/dts/arm/renesas/ra/ra4/ra4-cm33-common.dtsi:329 */
		dac_global: dac_global@40171000 {
			compatible = "renesas,ra-dac-global"; /* in zephyr/dts/arm/renesas/ra/ra4/ra4-cm33-common.dtsi:330 */
			reg = < 0x40171000 0x10c4 >;          /* in zephyr/dts/arm/renesas/ra/ra4/ra4-cm33-common.dtsi:331 */
			#address-cells = < 0x1 >;             /* in zephyr/dts/arm/renesas/ra/ra4/ra4-cm33-common.dtsi:332 */
			#size-cells = < 0x0 >;                /* in zephyr/dts/arm/renesas/ra/ra4/ra4-cm33-common.dtsi:333 */
			has-output-amplifier;                 /* in zephyr/dts/arm/renesas/ra/ra4/r7fa4e2b93cfm.dtsi:379 */

			/* node '/soc/dac_global@40171000/dac@0' defined in zephyr/dts/arm/renesas/ra/ra4/ra4-cm33-common.dtsi:335 */
			dac0: dac@0 {
				compatible = "renesas,ra-dac"; /* in zephyr/dts/arm/renesas/ra/ra4/ra4-cm33-common.dtsi:336 */
				#io-channel-cells = < 0x1 >;   /* in zephyr/dts/arm/renesas/ra/ra4/ra4-cm33-common.dtsi:337 */
				reg = < 0x0 >;                 /* in zephyr/dts/arm/renesas/ra/ra4/ra4-cm33-common.dtsi:338 */
				pinctrl-0 = < &dac0_default >; /* in zephyr/boards/renesas/ek_ra4e2/ek_ra4e2.dts:176 */
				pinctrl-names = "default";     /* in zephyr/boards/renesas/ek_ra4e2/ek_ra4e2.dts:177 */
				status = "okay";               /* in zephyr/boards/renesas/ek_ra4e2/ek_ra4e2.dts:178 */
			};
		};

		/* node '/soc/external-interrupt@40006000' defined in zephyr/dts/arm/renesas/ra/ra4/ra4-cm33-common.dtsi:380 */
		port_irq0: external-interrupt@40006000 {
			compatible = "renesas,ra-external-interrupt"; /* in zephyr/dts/arm/renesas/ra/ra4/ra4-cm33-common.dtsi:381 */
			reg = < 0x40006000 0x1 >;                     /* in zephyr/dts/arm/renesas/ra/ra4/ra4-cm33-common.dtsi:382 */
			channel = < 0x0 >;                            /* in zephyr/dts/arm/renesas/ra/ra4/ra4-cm33-common.dtsi:383 */
			renesas,sample-clock-div = < 0x40 >;          /* in zephyr/dts/arm/renesas/ra/ra4/ra4-cm33-common.dtsi:384 */
			#port-irq-cells = < 0x0 >;                    /* in zephyr/dts/arm/renesas/ra/ra4/ra4-cm33-common.dtsi:385 */
			status = "disabled";                          /* in zephyr/dts/arm/renesas/ra/ra4/ra4-cm33-common.dtsi:386 */
			phandle = < 0xc >;                            /* in zephyr/dts/arm/renesas/ra/ra4/r7fa4e2b93cfm.dtsi:317 */
		};

		/* node '/soc/external-interrupt@40006001' defined in zephyr/dts/arm/renesas/ra/ra4/ra4-cm33-common.dtsi:389 */
		port_irq1: external-interrupt@40006001 {
			compatible = "renesas,ra-external-interrupt"; /* in zephyr/dts/arm/renesas/ra/ra4/ra4-cm33-common.dtsi:390 */
			reg = < 0x40006001 0x1 >;                     /* in zephyr/dts/arm/renesas/ra/ra4/ra4-cm33-common.dtsi:391 */
			channel = < 0x1 >;                            /* in zephyr/dts/arm/renesas/ra/ra4/ra4-cm33-common.dtsi:392 */
			renesas,sample-clock-div = < 0x40 >;          /* in zephyr/dts/arm/renesas/ra/ra4/ra4-cm33-common.dtsi:393 */
			#port-irq-cells = < 0x0 >;                    /* in zephyr/dts/arm/renesas/ra/ra4/ra4-cm33-common.dtsi:394 */
			status = "disabled";                          /* in zephyr/dts/arm/renesas/ra/ra4/ra4-cm33-common.dtsi:395 */
			phandle = < 0xd >;                            /* in zephyr/dts/arm/renesas/ra/ra4/r7fa4e2b93cfm.dtsi:317 */
		};

		/* node '/soc/external-interrupt@40006002' defined in zephyr/dts/arm/renesas/ra/ra4/ra4-cm33-common.dtsi:398 */
		port_irq2: external-interrupt@40006002 {
			compatible = "renesas,ra-external-interrupt"; /* in zephyr/dts/arm/renesas/ra/ra4/ra4-cm33-common.dtsi:399 */
			reg = < 0x40006002 0x1 >;                     /* in zephyr/dts/arm/renesas/ra/ra4/ra4-cm33-common.dtsi:400 */
			channel = < 0x2 >;                            /* in zephyr/dts/arm/renesas/ra/ra4/ra4-cm33-common.dtsi:401 */
			renesas,sample-clock-div = < 0x40 >;          /* in zephyr/dts/arm/renesas/ra/ra4/ra4-cm33-common.dtsi:402 */
			#port-irq-cells = < 0x0 >;                    /* in zephyr/dts/arm/renesas/ra/ra4/ra4-cm33-common.dtsi:403 */
			status = "disabled";                          /* in zephyr/dts/arm/renesas/ra/ra4/ra4-cm33-common.dtsi:404 */
			phandle = < 0xe >;                            /* in zephyr/dts/arm/renesas/ra/ra4/r7fa4e2b93cfm.dtsi:317 */
		};

		/* node '/soc/external-interrupt@40006003' defined in zephyr/dts/arm/renesas/ra/ra4/ra4-cm33-common.dtsi:407 */
		port_irq3: external-interrupt@40006003 {
			compatible = "renesas,ra-external-interrupt"; /* in zephyr/dts/arm/renesas/ra/ra4/ra4-cm33-common.dtsi:408 */
			reg = < 0x40006003 0x1 >;                     /* in zephyr/dts/arm/renesas/ra/ra4/ra4-cm33-common.dtsi:409 */
			channel = < 0x3 >;                            /* in zephyr/dts/arm/renesas/ra/ra4/ra4-cm33-common.dtsi:410 */
			renesas,sample-clock-div = < 0x40 >;          /* in zephyr/dts/arm/renesas/ra/ra4/ra4-cm33-common.dtsi:411 */
			#port-irq-cells = < 0x0 >;                    /* in zephyr/dts/arm/renesas/ra/ra4/ra4-cm33-common.dtsi:412 */
			status = "disabled";                          /* in zephyr/dts/arm/renesas/ra/ra4/ra4-cm33-common.dtsi:413 */
			phandle = < 0xf >;                            /* in zephyr/dts/arm/renesas/ra/ra4/r7fa4e2b93cfm.dtsi:317 */
		};

		/* node '/soc/external-interrupt@40006004' defined in zephyr/dts/arm/renesas/ra/ra4/ra4-cm33-common.dtsi:416 */
		port_irq4: external-interrupt@40006004 {
			compatible = "renesas,ra-external-interrupt"; /* in zephyr/dts/arm/renesas/ra/ra4/ra4-cm33-common.dtsi:417 */
			reg = < 0x40006004 0x1 >;                     /* in zephyr/dts/arm/renesas/ra/ra4/ra4-cm33-common.dtsi:418 */
			channel = < 0x4 >;                            /* in zephyr/dts/arm/renesas/ra/ra4/ra4-cm33-common.dtsi:419 */
			renesas,sample-clock-div = < 0x40 >;          /* in zephyr/dts/arm/renesas/ra/ra4/ra4-cm33-common.dtsi:420 */
			#port-irq-cells = < 0x0 >;                    /* in zephyr/dts/arm/renesas/ra/ra4/ra4-cm33-common.dtsi:421 */
			status = "disabled";                          /* in zephyr/dts/arm/renesas/ra/ra4/ra4-cm33-common.dtsi:422 */
			phandle = < 0x10 >;                           /* in zephyr/dts/arm/renesas/ra/ra4/r7fa4e2b93cfm.dtsi:317 */
		};

		/* node '/soc/external-interrupt@40006005' defined in zephyr/dts/arm/renesas/ra/ra4/ra4-cm33-common.dtsi:425 */
		port_irq5: external-interrupt@40006005 {
			compatible = "renesas,ra-external-interrupt"; /* in zephyr/dts/arm/renesas/ra/ra4/ra4-cm33-common.dtsi:426 */
			reg = < 0x40006005 0x1 >;                     /* in zephyr/dts/arm/renesas/ra/ra4/ra4-cm33-common.dtsi:427 */
			channel = < 0x5 >;                            /* in zephyr/dts/arm/renesas/ra/ra4/ra4-cm33-common.dtsi:428 */
			renesas,sample-clock-div = < 0x40 >;          /* in zephyr/dts/arm/renesas/ra/ra4/ra4-cm33-common.dtsi:429 */
			#port-irq-cells = < 0x0 >;                    /* in zephyr/dts/arm/renesas/ra/ra4/ra4-cm33-common.dtsi:430 */
			status = "disabled";                          /* in zephyr/dts/arm/renesas/ra/ra4/ra4-cm33-common.dtsi:431 */
			phandle = < 0x11 >;                           /* in zephyr/dts/arm/renesas/ra/ra4/r7fa4e2b93cfm.dtsi:345 */
		};

		/* node '/soc/external-interrupt@40006006' defined in zephyr/dts/arm/renesas/ra/ra4/ra4-cm33-common.dtsi:434 */
		port_irq6: external-interrupt@40006006 {
			compatible = "renesas,ra-external-interrupt"; /* in zephyr/dts/arm/renesas/ra/ra4/ra4-cm33-common.dtsi:435 */
			reg = < 0x40006006 0x1 >;                     /* in zephyr/dts/arm/renesas/ra/ra4/ra4-cm33-common.dtsi:436 */
			channel = < 0x6 >;                            /* in zephyr/dts/arm/renesas/ra/ra4/ra4-cm33-common.dtsi:437 */
			renesas,sample-clock-div = < 0x40 >;          /* in zephyr/dts/arm/renesas/ra/ra4/ra4-cm33-common.dtsi:438 */
			#port-irq-cells = < 0x0 >;                    /* in zephyr/dts/arm/renesas/ra/ra4/ra4-cm33-common.dtsi:439 */
			status = "disabled";                          /* in zephyr/dts/arm/renesas/ra/ra4/ra4-cm33-common.dtsi:440 */
			phandle = < 0x4 >;                            /* in zephyr/dts/arm/renesas/ra/ra4/r7fa4e2b93cfm.dtsi:295 */
		};

		/* node '/soc/external-interrupt@40006007' defined in zephyr/dts/arm/renesas/ra/ra4/ra4-cm33-common.dtsi:443 */
		port_irq7: external-interrupt@40006007 {
			compatible = "renesas,ra-external-interrupt"; /* in zephyr/dts/arm/renesas/ra/ra4/ra4-cm33-common.dtsi:444 */
			reg = < 0x40006007 0x1 >;                     /* in zephyr/dts/arm/renesas/ra/ra4/ra4-cm33-common.dtsi:445 */
			channel = < 0x7 >;                            /* in zephyr/dts/arm/renesas/ra/ra4/ra4-cm33-common.dtsi:446 */
			renesas,sample-clock-div = < 0x40 >;          /* in zephyr/dts/arm/renesas/ra/ra4/ra4-cm33-common.dtsi:447 */
			#port-irq-cells = < 0x0 >;                    /* in zephyr/dts/arm/renesas/ra/ra4/ra4-cm33-common.dtsi:448 */
			status = "disabled";                          /* in zephyr/dts/arm/renesas/ra/ra4/ra4-cm33-common.dtsi:449 */
			phandle = < 0x5 >;                            /* in zephyr/dts/arm/renesas/ra/ra4/r7fa4e2b93cfm.dtsi:295 */
		};

		/* node '/soc/external-interrupt@40006008' defined in zephyr/dts/arm/renesas/ra/ra4/ra4-cm33-common.dtsi:452 */
		port_irq8: external-interrupt@40006008 {
			compatible = "renesas,ra-external-interrupt"; /* in zephyr/dts/arm/renesas/ra/ra4/ra4-cm33-common.dtsi:453 */
			reg = < 0x40006008 0x1 >;                     /* in zephyr/dts/arm/renesas/ra/ra4/ra4-cm33-common.dtsi:454 */
			channel = < 0x8 >;                            /* in zephyr/dts/arm/renesas/ra/ra4/ra4-cm33-common.dtsi:455 */
			renesas,sample-clock-div = < 0x40 >;          /* in zephyr/dts/arm/renesas/ra/ra4/ra4-cm33-common.dtsi:456 */
			#port-irq-cells = < 0x0 >;                    /* in zephyr/dts/arm/renesas/ra/ra4/ra4-cm33-common.dtsi:457 */
			status = "disabled";                          /* in zephyr/dts/arm/renesas/ra/ra4/ra4-cm33-common.dtsi:458 */
			phandle = < 0x6 >;                            /* in zephyr/dts/arm/renesas/ra/ra4/r7fa4e2b93cfm.dtsi:295 */
		};

		/* node '/soc/external-interrupt@40006009' defined in zephyr/dts/arm/renesas/ra/ra4/ra4-cm33-common.dtsi:461 */
		port_irq9: external-interrupt@40006009 {
			compatible = "renesas,ra-external-interrupt"; /* in zephyr/dts/arm/renesas/ra/ra4/ra4-cm33-common.dtsi:462 */
			reg = < 0x40006009 0x1 >;                     /* in zephyr/dts/arm/renesas/ra/ra4/ra4-cm33-common.dtsi:463 */
			channel = < 0x9 >;                            /* in zephyr/dts/arm/renesas/ra/ra4/ra4-cm33-common.dtsi:464 */
			renesas,sample-clock-div = < 0x40 >;          /* in zephyr/dts/arm/renesas/ra/ra4/ra4-cm33-common.dtsi:465 */
			#port-irq-cells = < 0x0 >;                    /* in zephyr/dts/arm/renesas/ra/ra4/ra4-cm33-common.dtsi:466 */
			interrupts = < 0x4 0xc >;                     /* in zephyr/boards/renesas/ek_ra4e2/ek_ra4e2.dts:186 */
			status = "okay";                              /* in zephyr/boards/renesas/ek_ra4e2/ek_ra4e2.dts:187 */
			phandle = < 0x7 >;                            /* in zephyr/dts/arm/renesas/ra/ra4/r7fa4e2b93cfm.dtsi:295 */
		};

		/* node '/soc/external-interrupt@4000600a' defined in zephyr/dts/arm/renesas/ra/ra4/ra4-cm33-common.dtsi:470 */
		port_irq10: external-interrupt@4000600a {
			compatible = "renesas,ra-external-interrupt"; /* in zephyr/dts/arm/renesas/ra/ra4/ra4-cm33-common.dtsi:471 */
			reg = < 0x4000600a 0x1 >;                     /* in zephyr/dts/arm/renesas/ra/ra4/ra4-cm33-common.dtsi:472 */
			channel = < 0xa >;                            /* in zephyr/dts/arm/renesas/ra/ra4/ra4-cm33-common.dtsi:473 */
			renesas,sample-clock-div = < 0x40 >;          /* in zephyr/dts/arm/renesas/ra/ra4/ra4-cm33-common.dtsi:474 */
			#port-irq-cells = < 0x0 >;                    /* in zephyr/dts/arm/renesas/ra/ra4/ra4-cm33-common.dtsi:475 */
			interrupts = < 0x5 0xc >;                     /* in zephyr/boards/renesas/ek_ra4e2/ek_ra4e2.dts:191 */
			status = "okay";                              /* in zephyr/boards/renesas/ek_ra4e2/ek_ra4e2.dts:192 */
			phandle = < 0x8 >;                            /* in zephyr/dts/arm/renesas/ra/ra4/r7fa4e2b93cfm.dtsi:295 */
		};

		/* node '/soc/external-interrupt@4000600b' defined in zephyr/dts/arm/renesas/ra/ra4/ra4-cm33-common.dtsi:479 */
		port_irq11: external-interrupt@4000600b {
			compatible = "renesas,ra-external-interrupt"; /* in zephyr/dts/arm/renesas/ra/ra4/ra4-cm33-common.dtsi:480 */
			reg = < 0x4000600b 0x1 >;                     /* in zephyr/dts/arm/renesas/ra/ra4/ra4-cm33-common.dtsi:481 */
			channel = < 0xb >;                            /* in zephyr/dts/arm/renesas/ra/ra4/ra4-cm33-common.dtsi:482 */
			renesas,sample-clock-div = < 0x40 >;          /* in zephyr/dts/arm/renesas/ra/ra4/ra4-cm33-common.dtsi:483 */
			#port-irq-cells = < 0x0 >;                    /* in zephyr/dts/arm/renesas/ra/ra4/ra4-cm33-common.dtsi:484 */
			status = "disabled";                          /* in zephyr/dts/arm/renesas/ra/ra4/ra4-cm33-common.dtsi:485 */
			phandle = < 0x9 >;                            /* in zephyr/dts/arm/renesas/ra/ra4/r7fa4e2b93cfm.dtsi:295 */
		};

		/* node '/soc/external-interrupt@4000600c' defined in zephyr/dts/arm/renesas/ra/ra4/ra4-cm33-common.dtsi:488 */
		port_irq12: external-interrupt@4000600c {
			compatible = "renesas,ra-external-interrupt"; /* in zephyr/dts/arm/renesas/ra/ra4/ra4-cm33-common.dtsi:489 */
			reg = < 0x4000600c 0x1 >;                     /* in zephyr/dts/arm/renesas/ra/ra4/ra4-cm33-common.dtsi:490 */
			channel = < 0xc >;                            /* in zephyr/dts/arm/renesas/ra/ra4/ra4-cm33-common.dtsi:491 */
			renesas,sample-clock-div = < 0x40 >;          /* in zephyr/dts/arm/renesas/ra/ra4/ra4-cm33-common.dtsi:492 */
			#port-irq-cells = < 0x0 >;                    /* in zephyr/dts/arm/renesas/ra/ra4/ra4-cm33-common.dtsi:493 */
			status = "disabled";                          /* in zephyr/dts/arm/renesas/ra/ra4/ra4-cm33-common.dtsi:494 */
			phandle = < 0xa >;                            /* in zephyr/dts/arm/renesas/ra/ra4/r7fa4e2b93cfm.dtsi:295 */
		};

		/* node '/soc/external-interrupt@4000600d' defined in zephyr/dts/arm/renesas/ra/ra4/ra4-cm33-common.dtsi:497 */
		port_irq13: external-interrupt@4000600d {
			compatible = "renesas,ra-external-interrupt"; /* in zephyr/dts/arm/renesas/ra/ra4/ra4-cm33-common.dtsi:498 */
			reg = < 0x4000600d 0x1 >;                     /* in zephyr/dts/arm/renesas/ra/ra4/ra4-cm33-common.dtsi:499 */
			channel = < 0xd >;                            /* in zephyr/dts/arm/renesas/ra/ra4/ra4-cm33-common.dtsi:500 */
			renesas,sample-clock-div = < 0x40 >;          /* in zephyr/dts/arm/renesas/ra/ra4/ra4-cm33-common.dtsi:501 */
			#port-irq-cells = < 0x0 >;                    /* in zephyr/dts/arm/renesas/ra/ra4/ra4-cm33-common.dtsi:502 */
			status = "disabled";                          /* in zephyr/dts/arm/renesas/ra/ra4/ra4-cm33-common.dtsi:503 */
			phandle = < 0xb >;                            /* in zephyr/dts/arm/renesas/ra/ra4/r7fa4e2b93cfm.dtsi:295 */
		};

		/* node '/soc/external-interrupt@4000600e' defined in zephyr/dts/arm/renesas/ra/ra4/ra4-cm33-common.dtsi:506 */
		port_irq14: external-interrupt@4000600e {
			compatible = "renesas,ra-external-interrupt"; /* in zephyr/dts/arm/renesas/ra/ra4/ra4-cm33-common.dtsi:507 */
			reg = < 0x4000600e 0x1 >;                     /* in zephyr/dts/arm/renesas/ra/ra4/ra4-cm33-common.dtsi:508 */
			channel = < 0xe >;                            /* in zephyr/dts/arm/renesas/ra/ra4/ra4-cm33-common.dtsi:509 */
			renesas,sample-clock-div = < 0x40 >;          /* in zephyr/dts/arm/renesas/ra/ra4/ra4-cm33-common.dtsi:510 */
			#port-irq-cells = < 0x0 >;                    /* in zephyr/dts/arm/renesas/ra/ra4/ra4-cm33-common.dtsi:511 */
			status = "disabled";                          /* in zephyr/dts/arm/renesas/ra/ra4/ra4-cm33-common.dtsi:512 */
			phandle = < 0x12 >;                           /* in zephyr/dts/arm/renesas/ra/ra4/r7fa4e2b93cfm.dtsi:355 */
		};

		/* node '/soc/external-interrupt@4000600f' defined in zephyr/dts/arm/renesas/ra/ra4/ra4-cm33-common.dtsi:515 */
		port_irq15: external-interrupt@4000600f {
			compatible = "renesas,ra-external-interrupt"; /* in zephyr/dts/arm/renesas/ra/ra4/ra4-cm33-common.dtsi:516 */
			reg = < 0x4000600f 0x1 >;                     /* in zephyr/dts/arm/renesas/ra/ra4/ra4-cm33-common.dtsi:517 */
			channel = < 0xf >;                            /* in zephyr/dts/arm/renesas/ra/ra4/ra4-cm33-common.dtsi:518 */
			renesas,sample-clock-div = < 0x40 >;          /* in zephyr/dts/arm/renesas/ra/ra4/ra4-cm33-common.dtsi:519 */
			#port-irq-cells = < 0x0 >;                    /* in zephyr/dts/arm/renesas/ra/ra4/ra4-cm33-common.dtsi:520 */
			status = "disabled";                          /* in zephyr/dts/arm/renesas/ra/ra4/ra4-cm33-common.dtsi:521 */
		};

		/* node '/soc/pwm0@40169000' defined in zephyr/dts/arm/renesas/ra/ra4/ra4-cm33-common.dtsi:524 */
		pwm0: pwm0@40169000 {
			compatible = "renesas,ra-pwm"; /* in zephyr/dts/arm/renesas/ra/ra4/ra4-cm33-common.dtsi:525 */
			divider = < 0x0 >;             /* in zephyr/dts/arm/renesas/ra/ra4/ra4-cm33-common.dtsi:526 */
			channel = < 0x0 >;             /* in zephyr/dts/arm/renesas/ra/ra4/ra4-cm33-common.dtsi:527 */
			clocks = < &pclkd 0x4 0x1f >;  /* in zephyr/dts/arm/renesas/ra/ra4/ra4-cm33-common.dtsi:528 */
			reg = < 0x40169000 0x100 >;    /* in zephyr/dts/arm/renesas/ra/ra4/ra4-cm33-common.dtsi:529 */
			#pwm-cells = < 0x3 >;          /* in zephyr/dts/arm/renesas/ra/ra4/ra4-cm33-common.dtsi:530 */
			status = "disabled";           /* in zephyr/dts/arm/renesas/ra/ra4/ra4-cm33-common.dtsi:531 */
		};

		/* node '/soc/pwm1@40169100' defined in zephyr/dts/arm/renesas/ra/ra4/ra4-cm33-common.dtsi:534 */
		pwm1: pwm1@40169100 {
			compatible = "renesas,ra-pwm"; /* in zephyr/dts/arm/renesas/ra/ra4/ra4-cm33-common.dtsi:535 */
			channel = < 0x1 >;             /* in zephyr/dts/arm/renesas/ra/ra4/ra4-cm33-common.dtsi:537 */
			clocks = < &pclkd 0x4 0x1e >;  /* in zephyr/dts/arm/renesas/ra/ra4/ra4-cm33-common.dtsi:538 */
			reg = < 0x40169100 0x100 >;    /* in zephyr/dts/arm/renesas/ra/ra4/ra4-cm33-common.dtsi:539 */
			#pwm-cells = < 0x3 >;          /* in zephyr/dts/arm/renesas/ra/ra4/ra4-cm33-common.dtsi:540 */
			pinctrl-0 = < &pwm1_default >; /* in zephyr/boards/renesas/ek_ra4e2/ek_ra4e2.dts:196 */
			pinctrl-names = "default";     /* in zephyr/boards/renesas/ek_ra4e2/ek_ra4e2.dts:197 */
			interrupts = < 0x3f 0x1 >,
			             < 0x40 0x1 >;     /* in zephyr/boards/renesas/ek_ra4e2/ek_ra4e2.dts:198 */
			interrupt-names = "gtioca",
			                  "overflow";  /* in zephyr/boards/renesas/ek_ra4e2/ek_ra4e2.dts:199 */
			divider = < 0x8 >;             /* in zephyr/boards/renesas/ek_ra4e2/ek_ra4e2.dts:200 */
			status = "okay";               /* in zephyr/boards/renesas/ek_ra4e2/ek_ra4e2.dts:201 */
		};

		/* node '/soc/pwm4@40169400' defined in zephyr/dts/arm/renesas/ra/ra4/ra4-cm33-common.dtsi:544 */
		pwm4: pwm4@40169400 {
			compatible = "renesas,ra-pwm"; /* in zephyr/dts/arm/renesas/ra/ra4/ra4-cm33-common.dtsi:545 */
			divider = < 0x0 >;             /* in zephyr/dts/arm/renesas/ra/ra4/ra4-cm33-common.dtsi:546 */
			channel = < 0x4 >;             /* in zephyr/dts/arm/renesas/ra/ra4/ra4-cm33-common.dtsi:547 */
			clocks = < &pclkd 0x4 0x1b >;  /* in zephyr/dts/arm/renesas/ra/ra4/ra4-cm33-common.dtsi:548 */
			reg = < 0x40169400 0x100 >;    /* in zephyr/dts/arm/renesas/ra/ra4/ra4-cm33-common.dtsi:549 */
			#pwm-cells = < 0x3 >;          /* in zephyr/dts/arm/renesas/ra/ra4/ra4-cm33-common.dtsi:550 */
			status = "disabled";           /* in zephyr/dts/arm/renesas/ra/ra4/ra4-cm33-common.dtsi:551 */
		};

		/* node '/soc/pwm5@40169500' defined in zephyr/dts/arm/renesas/ra/ra4/ra4-cm33-common.dtsi:554 */
		pwm5: pwm5@40169500 {
			compatible = "renesas,ra-pwm"; /* in zephyr/dts/arm/renesas/ra/ra4/ra4-cm33-common.dtsi:555 */
			divider = < 0x0 >;             /* in zephyr/dts/arm/renesas/ra/ra4/ra4-cm33-common.dtsi:556 */
			channel = < 0x5 >;             /* in zephyr/dts/arm/renesas/ra/ra4/ra4-cm33-common.dtsi:557 */
			clocks = < &pclkd 0x4 0x1a >;  /* in zephyr/dts/arm/renesas/ra/ra4/ra4-cm33-common.dtsi:558 */
			reg = < 0x40169500 0x100 >;    /* in zephyr/dts/arm/renesas/ra/ra4/ra4-cm33-common.dtsi:559 */
			#pwm-cells = < 0x3 >;          /* in zephyr/dts/arm/renesas/ra/ra4/ra4-cm33-common.dtsi:560 */
			status = "disabled";           /* in zephyr/dts/arm/renesas/ra/ra4/ra4-cm33-common.dtsi:561 */
		};

		/* node '/soc/wdt@40083400' defined in zephyr/dts/arm/renesas/ra/ra4/ra4-cm33-common.dtsi:564 */
		wdt: wdt@40083400 {
			compatible = "renesas,ra-wdt"; /* in zephyr/dts/arm/renesas/ra/ra4/ra4-cm33-common.dtsi:565 */
			reg = < 0x40083400 0x200 >;    /* in zephyr/dts/arm/renesas/ra/ra4/ra4-cm33-common.dtsi:566 */
			clocks = < &pclkb 0x0 0x0 >;   /* in zephyr/dts/arm/renesas/ra/ra4/ra4-cm33-common.dtsi:567 */
			status = "okay";               /* in zephyr/boards/renesas/ek_ra4e2/ek_ra4e2.dts:222 */
		};

		/* node '/soc/memory@20000000' defined in zephyr/dts/arm/renesas/ra/ra4/r7fa4e2b93cfm.dtsi:27 */
		sram0: memory@20000000 {
			compatible = "mmio-sram";    /* in zephyr/dts/arm/renesas/ra/ra4/r7fa4e2b93cfm.dtsi:28 */
			reg = < 0x20000000 0xa000 >; /* in zephyr/dts/arm/renesas/ra/ra4/r7fa4e2b93cfm.dtsi:29 */
		};

		/* node '/soc/gpio@40080100' defined in zephyr/dts/arm/renesas/ra/ra4/r7fa4e2b93cfm.dtsi:32 */
		ioport8: gpio@40080100 {
			compatible = "renesas,ra-gpio-ioport"; /* in zephyr/dts/arm/renesas/ra/ra4/r7fa4e2b93cfm.dtsi:33 */
			reg = < 0x40080100 0x20 >;             /* in zephyr/dts/arm/renesas/ra/ra4/r7fa4e2b93cfm.dtsi:34 */
			port = < 0x8 >;                        /* in zephyr/dts/arm/renesas/ra/ra4/r7fa4e2b93cfm.dtsi:35 */
			gpio-controller;                       /* in zephyr/dts/arm/renesas/ra/ra4/r7fa4e2b93cfm.dtsi:36 */
			#gpio-cells = < 0x2 >;                 /* in zephyr/dts/arm/renesas/ra/ra4/r7fa4e2b93cfm.dtsi:37 */
			ngpios = < 0x10 >;                     /* in zephyr/dts/arm/renesas/ra/ra4/r7fa4e2b93cfm.dtsi:38 */
			status = "disabled";                   /* in zephyr/dts/arm/renesas/ra/ra4/r7fa4e2b93cfm.dtsi:39 */
			port-irqs = < &port_irq11 >;           /* in zephyr/dts/arm/renesas/ra/ra4/r7fa4e2b93cfm.dtsi:373 */
			port-irq-names = "port-irq11";         /* in zephyr/dts/arm/renesas/ra/ra4/r7fa4e2b93cfm.dtsi:374 */
			port-irq11-pins = < 0xe >;             /* in zephyr/dts/arm/renesas/ra/ra4/r7fa4e2b93cfm.dtsi:375 */
		};

		/* node '/soc/canfd_global@400b0000' defined in zephyr/dts/arm/renesas/ra/ra4/r7fa4e2b93cfm.dtsi:69 */
		canfd_global: canfd_global@400b0000 {
			compatible = "renesas,ra-canfd-global"; /* in zephyr/dts/arm/renesas/ra/ra4/r7fa4e2b93cfm.dtsi:70 */
			interrupts = < 0x28 0x1 >,
			             < 0x29 0x1 >;              /* in zephyr/dts/arm/renesas/ra/ra4/r7fa4e2b93cfm.dtsi:71 */
			interrupt-names = "rxf",
			                  "glerr";              /* in zephyr/dts/arm/renesas/ra/ra4/r7fa4e2b93cfm.dtsi:72 */
			clocks = < &pclkb 0x0 0x0 >,
			         < &pclka 0x0 0x0 >;            /* in zephyr/dts/arm/renesas/ra/ra4/r7fa4e2b93cfm.dtsi:73 */
			clock-names = "opclk",
			              "ramclk";                 /* in zephyr/dts/arm/renesas/ra/ra4/r7fa4e2b93cfm.dtsi:74 */
			dll-max-freq = < 0x2625a00 >;           /* in zephyr/dts/arm/renesas/ra/ra4/r7fa4e2b93cfm.dtsi:75 */
			reg = < 0x400b0000 0x2000 >;            /* in zephyr/dts/arm/renesas/ra/ra4/r7fa4e2b93cfm.dtsi:76 */
			status = "okay";                        /* in zephyr/boards/renesas/ek_ra4e2/ek_ra4e2.dts:158 */

			/* node '/soc/canfd_global@400b0000/canfd0' defined in zephyr/dts/arm/renesas/ra/ra4/r7fa4e2b93cfm.dtsi:79 */
			canfd0: canfd0 {
				compatible = "renesas,ra-canfd"; /* in zephyr/dts/arm/renesas/ra/ra4/r7fa4e2b93cfm.dtsi:80 */
				channel = < 0x0 >;               /* in zephyr/dts/arm/renesas/ra/ra4/r7fa4e2b93cfm.dtsi:81 */
				interrupts = < 0x2b 0xc >,
				             < 0x2c 0xc >,
				             < 0x2d 0xc >;       /* in zephyr/dts/arm/renesas/ra/ra4/r7fa4e2b93cfm.dtsi:82 */
				interrupt-names = "err",
				                  "tx",
				                  "rx";          /* in zephyr/dts/arm/renesas/ra/ra4/r7fa4e2b93cfm.dtsi:83 */
				clocks = < &canfdclk 0x2 0x1b >; /* in zephyr/dts/arm/renesas/ra/ra4/r7fa4e2b93cfm.dtsi:84 */
				clock-names = "dllclk";          /* in zephyr/dts/arm/renesas/ra/ra4/r7fa4e2b93cfm.dtsi:85 */
				pinctrl-0 = < &canfd0_default >; /* in zephyr/boards/renesas/ek_ra4e2/ek_ra4e2.dts:161 */
				pinctrl-names = "default";       /* in zephyr/boards/renesas/ek_ra4e2/ek_ra4e2.dts:162 */
				phys = < &transceiver0 >;        /* in zephyr/boards/renesas/ek_ra4e2/ek_ra4e2.dts:163 */
				rx-max-filters = < 0x10 >;       /* in zephyr/boards/renesas/ek_ra4e2/ek_ra4e2.dts:164 */
				status = "okay";                 /* in zephyr/boards/renesas/ek_ra4e2/ek_ra4e2.dts:165 */
			};
		};

		/* node '/soc/trng' defined in zephyr/dts/arm/renesas/ra/ra4/r7fa4e2b93cfm.dtsi:90 */
		trng: trng {
			compatible = "renesas,ra-trng"; /* in zephyr/dts/arm/renesas/ra/ra4/r7fa4e2b93cfm.dtsi:91 */
			status = "okay";                /* in zephyr/boards/renesas/ek_ra4e2/ek_ra4e2.dts:205 */
		};

		/* node '/soc/agtw@400e8000' defined in zephyr/dts/arm/renesas/ra/ra4/r7fa4e2b93cfm.dtsi:95 */
		agt0: agtw@400e8000 {
			compatible = "renesas,ra-agt";           /* in zephyr/dts/arm/renesas/ra/ra4/r7fa4e2b93cfm.dtsi:96 */
			channel = < 0x0 >;                       /* in zephyr/dts/arm/renesas/ra/ra4/r7fa4e2b93cfm.dtsi:97 */
			reg = < 0x400e8000 0x100 >;              /* in zephyr/dts/arm/renesas/ra/ra4/r7fa4e2b93cfm.dtsi:98 */
			renesas,count-source = "AGT_CLOCK_LOCO"; /* in zephyr/dts/arm/renesas/ra/ra4/r7fa4e2b93cfm.dtsi:99 */
			renesas,prescaler = < 0x0 >;             /* in zephyr/dts/arm/renesas/ra/ra4/r7fa4e2b93cfm.dtsi:100 */
			renesas,resolution = < 0x20 >;           /* in zephyr/dts/arm/renesas/ra/ra4/r7fa4e2b93cfm.dtsi:101 */
			status = "disabled";                     /* in zephyr/dts/arm/renesas/ra/ra4/r7fa4e2b93cfm.dtsi:102 */

			/* node '/soc/agtw@400e8000/counter' defined in zephyr/dts/arm/renesas/ra/ra4/r7fa4e2b93cfm.dtsi:104 */
			counter {
				compatible = "renesas,ra-agt-counter"; /* in zephyr/dts/arm/renesas/ra/ra4/r7fa4e2b93cfm.dtsi:105 */
				status = "disabled";                   /* in zephyr/dts/arm/renesas/ra/ra4/r7fa4e2b93cfm.dtsi:106 */
			};
		};

		/* node '/soc/agtw@400e8100' defined in zephyr/dts/arm/renesas/ra/ra4/r7fa4e2b93cfm.dtsi:110 */
		agt1: agtw@400e8100 {
			compatible = "renesas,ra-agt";           /* in zephyr/dts/arm/renesas/ra/ra4/r7fa4e2b93cfm.dtsi:111 */
			channel = < 0x1 >;                       /* in zephyr/dts/arm/renesas/ra/ra4/r7fa4e2b93cfm.dtsi:112 */
			reg = < 0x400e8100 0x100 >;              /* in zephyr/dts/arm/renesas/ra/ra4/r7fa4e2b93cfm.dtsi:113 */
			renesas,count-source = "AGT_CLOCK_LOCO"; /* in zephyr/dts/arm/renesas/ra/ra4/r7fa4e2b93cfm.dtsi:114 */
			renesas,prescaler = < 0x0 >;             /* in zephyr/dts/arm/renesas/ra/ra4/r7fa4e2b93cfm.dtsi:115 */
			renesas,resolution = < 0x20 >;           /* in zephyr/dts/arm/renesas/ra/ra4/r7fa4e2b93cfm.dtsi:116 */
			status = "disabled";                     /* in zephyr/dts/arm/renesas/ra/ra4/r7fa4e2b93cfm.dtsi:117 */

			/* node '/soc/agtw@400e8100/counter' defined in zephyr/dts/arm/renesas/ra/ra4/r7fa4e2b93cfm.dtsi:119 */
			counter {
				compatible = "renesas,ra-agt-counter"; /* in zephyr/dts/arm/renesas/ra/ra4/r7fa4e2b93cfm.dtsi:120 */
				status = "disabled";                   /* in zephyr/dts/arm/renesas/ra/ra4/r7fa4e2b93cfm.dtsi:121 */
			};
		};

		/* node '/soc/option-setting-ofs0@100a100' defined in zephyr/dts/arm/renesas/ra/ra4/r7fa4e2b93cfm.dtsi:125 */
		option_setting_ofs0: option-setting-ofs0@100a100 {
			compatible = "zephyr,memory-region";      /* in zephyr/dts/arm/renesas/ra/ra4/r7fa4e2b93cfm.dtsi:126 */
			zephyr,memory-region = "OFS_OFS0_MEMORY"; /* in zephyr/dts/arm/renesas/ra/ra4/r7fa4e2b93cfm.dtsi:127 */
			reg = < 0x100a100 0x4 >;                  /* in zephyr/dts/arm/renesas/ra/ra4/r7fa4e2b93cfm.dtsi:128 */
			status = "okay";                          /* in zephyr/dts/arm/renesas/ra/ra4/r7fa4e2b93cfm.dtsi:129 */
		};

		/* node '/soc/option-setting-osis@100a120' defined in zephyr/dts/arm/renesas/ra/ra4/r7fa4e2b93cfm.dtsi:132 */
		option_setting_osis: option-setting-osis@100a120 {
			compatible = "zephyr,memory-region";      /* in zephyr/dts/arm/renesas/ra/ra4/r7fa4e2b93cfm.dtsi:133 */
			zephyr,memory-region = "OFS_OSIS_MEMORY"; /* in zephyr/dts/arm/renesas/ra/ra4/r7fa4e2b93cfm.dtsi:134 */
			reg = < 0x100a120 0x10 >;                 /* in zephyr/dts/arm/renesas/ra/ra4/r7fa4e2b93cfm.dtsi:135 */
			status = "okay";                          /* in zephyr/dts/arm/renesas/ra/ra4/r7fa4e2b93cfm.dtsi:136 */
		};

		/* node '/soc/option-setting-ofs1-sec@100a200' defined in zephyr/dts/arm/renesas/ra/ra4/r7fa4e2b93cfm.dtsi:139 */
		option_setting_ofs1_sec: option-setting-ofs1-sec@100a200 {
			compatible = "zephyr,memory-region";          /* in zephyr/dts/arm/renesas/ra/ra4/r7fa4e2b93cfm.dtsi:140 */
			zephyr,memory-region = "OFS_OFS1_SEC_MEMORY"; /* in zephyr/dts/arm/renesas/ra/ra4/r7fa4e2b93cfm.dtsi:141 */
			reg = < 0x100a200 0x4 >;                      /* in zephyr/dts/arm/renesas/ra/ra4/r7fa4e2b93cfm.dtsi:142 */
			status = "okay";                              /* in zephyr/dts/arm/renesas/ra/ra4/r7fa4e2b93cfm.dtsi:143 */
		};

		/* node '/soc/option-setting-bps-sec@100a240' defined in zephyr/dts/arm/renesas/ra/ra4/r7fa4e2b93cfm.dtsi:146 */
		option_setting_bps_sec: option-setting-bps-sec@100a240 {
			compatible = "zephyr,memory-region";         /* in zephyr/dts/arm/renesas/ra/ra4/r7fa4e2b93cfm.dtsi:147 */
			zephyr,memory-region = "OFS_BPS_SEC_MEMORY"; /* in zephyr/dts/arm/renesas/ra/ra4/r7fa4e2b93cfm.dtsi:148 */
			reg = < 0x100a240 0x4 >;                     /* in zephyr/dts/arm/renesas/ra/ra4/r7fa4e2b93cfm.dtsi:149 */
			status = "okay";                             /* in zephyr/dts/arm/renesas/ra/ra4/r7fa4e2b93cfm.dtsi:150 */
		};

		/* node '/soc/option-setting-pbps-sec@100a260' defined in zephyr/dts/arm/renesas/ra/ra4/r7fa4e2b93cfm.dtsi:153 */
		option_setting_pbps_sec: option-setting-pbps-sec@100a260 {
			compatible = "zephyr,memory-region";          /* in zephyr/dts/arm/renesas/ra/ra4/r7fa4e2b93cfm.dtsi:154 */
			zephyr,memory-region = "OFS_PBPS_SEC_MEMORY"; /* in zephyr/dts/arm/renesas/ra/ra4/r7fa4e2b93cfm.dtsi:155 */
			reg = < 0x100a260 0x4 >;                      /* in zephyr/dts/arm/renesas/ra/ra4/r7fa4e2b93cfm.dtsi:156 */
			status = "okay";                              /* in zephyr/dts/arm/renesas/ra/ra4/r7fa4e2b93cfm.dtsi:157 */
		};
	};

	/* node '/cpus' defined in zephyr/dts/arm/renesas/ra/ra4/ra4-cm33-common.dtsi:14 */
	cpus {
		#address-cells = < 0x1 >; /* in zephyr/dts/arm/renesas/ra/ra4/ra4-cm33-common.dtsi:15 */
		#size-cells = < 0x0 >;    /* in zephyr/dts/arm/renesas/ra/ra4/ra4-cm33-common.dtsi:16 */

		/* node '/cpus/cpu@0' defined in zephyr/dts/arm/renesas/ra/ra4/ra4-cm33-common.dtsi:18 */
		cpu@0 {
			device_type = "cpu";           /* in zephyr/dts/arm/renesas/ra/ra4/ra4-cm33-common.dtsi:19 */
			compatible = "arm,cortex-m33"; /* in zephyr/dts/arm/renesas/ra/ra4/ra4-cm33-common.dtsi:20 */
			reg = < 0x0 >;                 /* in zephyr/dts/arm/renesas/ra/ra4/ra4-cm33-common.dtsi:21 */
			#address-cells = < 0x1 >;      /* in zephyr/dts/arm/renesas/ra/ra4/ra4-cm33-common.dtsi:22 */
			#size-cells = < 0x1 >;         /* in zephyr/dts/arm/renesas/ra/ra4/ra4-cm33-common.dtsi:23 */

			/* node '/cpus/cpu@0/mpu@e000ed90' defined in zephyr/dts/arm/renesas/ra/ra4/ra4-cm33-common.dtsi:25 */
			mpu: mpu@e000ed90 {
				compatible = "arm,armv8m-mpu"; /* in zephyr/dts/arm/renesas/ra/ra4/ra4-cm33-common.dtsi:26 */
				reg = < 0xe000ed90 0x40 >;     /* in zephyr/dts/arm/renesas/ra/ra4/ra4-cm33-common.dtsi:27 */
			};
		};
	};

	/* node '/clocks' defined in zephyr/dts/arm/renesas/ra/ra4/r7fa4e2b93cfm.dtsi:161 */
	clocks: clocks {
		#address-cells = < 0x1 >; /* in zephyr/dts/arm/renesas/ra/ra4/r7fa4e2b93cfm.dtsi:162 */
		#size-cells = < 0x1 >;    /* in zephyr/dts/arm/renesas/ra/ra4/r7fa4e2b93cfm.dtsi:163 */

		/* node '/clocks/clock-main-osc' defined in zephyr/dts/arm/renesas/ra/ra4/r7fa4e2b93cfm.dtsi:165 */
		xtal: clock-main-osc {
			compatible = "renesas,ra-cgc-external-clock"; /* in zephyr/dts/arm/renesas/ra/ra4/r7fa4e2b93cfm.dtsi:166 */
			clock-frequency = < 0x1312d00 >;              /* in zephyr/boards/renesas/ek_ra4e2/ek_ra4e2.dts:85 */
			mosel = < 0x0 >;                              /* in zephyr/boards/renesas/ek_ra4e2/ek_ra4e2.dts:86 */
			#clock-cells = < 0x0 >;                       /* in zephyr/boards/renesas/ek_ra4e2/ek_ra4e2.dts:87 */
			status = "okay";                              /* in zephyr/boards/renesas/ek_ra4e2/ek_ra4e2.dts:88 */
			phandle = < 0x20 >;                           /* in zephyr/boards/renesas/ek_ra4e2/ek_ra4e2.dts:96 */
		};

		/* node '/clocks/clock-hoco' defined in zephyr/dts/arm/renesas/ra/ra4/r7fa4e2b93cfm.dtsi:172 */
		hoco: clock-hoco {
			compatible = "fixed-clock";      /* in zephyr/dts/arm/renesas/ra/ra4/r7fa4e2b93cfm.dtsi:173 */
			clock-frequency = < 0x1312d00 >; /* in zephyr/dts/arm/renesas/ra/ra4/r7fa4e2b93cfm.dtsi:174 */
			#clock-cells = < 0x0 >;          /* in zephyr/dts/arm/renesas/ra/ra4/r7fa4e2b93cfm.dtsi:175 */
		};

		/* node '/clocks/clock-moco' defined in zephyr/dts/arm/renesas/ra/ra4/r7fa4e2b93cfm.dtsi:178 */
		moco: clock-moco {
			compatible = "fixed-clock";     /* in zephyr/dts/arm/renesas/ra/ra4/r7fa4e2b93cfm.dtsi:179 */
			clock-frequency = < 0x7a1200 >; /* in zephyr/dts/arm/renesas/ra/ra4/r7fa4e2b93cfm.dtsi:180 */
			#clock-cells = < 0x0 >;         /* in zephyr/dts/arm/renesas/ra/ra4/r7fa4e2b93cfm.dtsi:181 */
		};

		/* node '/clocks/clock-loco' defined in zephyr/dts/arm/renesas/ra/ra4/r7fa4e2b93cfm.dtsi:184 */
		loco: clock-loco {
			compatible = "fixed-clock";   /* in zephyr/dts/arm/renesas/ra/ra4/r7fa4e2b93cfm.dtsi:185 */
			clock-frequency = < 0x8000 >; /* in zephyr/dts/arm/renesas/ra/ra4/r7fa4e2b93cfm.dtsi:186 */
			#clock-cells = < 0x0 >;       /* in zephyr/dts/arm/renesas/ra/ra4/r7fa4e2b93cfm.dtsi:187 */
		};

		/* node '/clocks/clock-subclk' defined in zephyr/dts/arm/renesas/ra/ra4/r7fa4e2b93cfm.dtsi:190 */
		subclk: clock-subclk {
			compatible = "renesas,ra-cgc-subclk"; /* in zephyr/dts/arm/renesas/ra/ra4/r7fa4e2b93cfm.dtsi:191 */
			clock-frequency = < 0x8000 >;         /* in zephyr/dts/arm/renesas/ra/ra4/r7fa4e2b93cfm.dtsi:192 */
			#clock-cells = < 0x0 >;               /* in zephyr/dts/arm/renesas/ra/ra4/r7fa4e2b93cfm.dtsi:193 */
			status = "okay";                      /* in zephyr/boards/renesas/ek_ra4e2/ek_ra4e2.dts:92 */
		};

		/* node '/clocks/pll' defined in zephyr/dts/arm/renesas/ra/ra4/r7fa4e2b93cfm.dtsi:197 */
		pll: pll {
			compatible = "renesas,ra-cgc-pll"; /* in zephyr/dts/arm/renesas/ra/ra4/r7fa4e2b93cfm.dtsi:198 */
			#clock-cells = < 0x0 >;            /* in zephyr/dts/arm/renesas/ra/ra4/r7fa4e2b93cfm.dtsi:199 */
			clocks = < &xtal >;                /* in zephyr/boards/renesas/ek_ra4e2/ek_ra4e2.dts:96 */
			div = < 0x1 >;                     /* in zephyr/boards/renesas/ek_ra4e2/ek_ra4e2.dts:97 */
			mul = < 0xa 0x0 >;                 /* in zephyr/boards/renesas/ek_ra4e2/ek_ra4e2.dts:98 */
			status = "okay";                   /* in zephyr/boards/renesas/ek_ra4e2/ek_ra4e2.dts:99 */
			phandle = < 0x21 >;                /* in zephyr/dts/arm/renesas/ra/ra4/r7fa4e2b93cfm.dtsi:215 */
		};

		/* node '/clocks/pclkblock@40084000' defined in zephyr/dts/arm/renesas/ra/ra4/r7fa4e2b93cfm.dtsi:208 */
		pclkblock: pclkblock@40084000 {
			compatible = "renesas,ra-cgc-pclk-block"; /* in zephyr/dts/arm/renesas/ra/ra4/r7fa4e2b93cfm.dtsi:209 */
			reg = < 0x40084000 0x4 >,
			      < 0x40084004 0x4 >,
			      < 0x40084008 0x4 >,
			      < 0x4008400c 0x4 >,
			      < 0x40084010 0x4 >;                 /* in zephyr/dts/arm/renesas/ra/ra4/r7fa4e2b93cfm.dtsi:210 */
			reg-names = "MSTPA",
			            "MSTPB",
			            "MSTPC",
			            "MSTPD",
			            "MSTPE";                      /* in zephyr/dts/arm/renesas/ra/ra4/r7fa4e2b93cfm.dtsi:212 */
			#clock-cells = < 0x0 >;                   /* in zephyr/dts/arm/renesas/ra/ra4/r7fa4e2b93cfm.dtsi:214 */
			clocks = < &pll >;                        /* in zephyr/dts/arm/renesas/ra/ra4/r7fa4e2b93cfm.dtsi:215 */
			status = "okay";                          /* in zephyr/dts/arm/renesas/ra/ra4/r7fa4e2b93cfm.dtsi:216 */

			/* node '/clocks/pclkblock@40084000/iclk' defined in zephyr/dts/arm/renesas/ra/ra4/r7fa4e2b93cfm.dtsi:218 */
			iclk: iclk {
				compatible = "renesas,ra-cgc-pclk"; /* in zephyr/dts/arm/renesas/ra/ra4/r7fa4e2b93cfm.dtsi:219 */
				clock-frequency = < 0x5f5e100 >;    /* in zephyr/dts/arm/renesas/ra/ra4/r7fa4e2b93cfm.dtsi:220 */
				div = < 0x2 >;                      /* in zephyr/dts/arm/renesas/ra/ra4/r7fa4e2b93cfm.dtsi:221 */
				#clock-cells = < 0x2 >;             /* in zephyr/dts/arm/renesas/ra/ra4/r7fa4e2b93cfm.dtsi:222 */
				status = "okay";                    /* in zephyr/dts/arm/renesas/ra/ra4/r7fa4e2b93cfm.dtsi:223 */
				phandle = < 0x13 >;                 /* in zephyr/dts/arm/renesas/ra/ra4/ra4-cm33-common.dtsi:123 */
			};

			/* node '/clocks/pclkblock@40084000/pclka' defined in zephyr/dts/arm/renesas/ra/ra4/r7fa4e2b93cfm.dtsi:226 */
			pclka: pclka {
				compatible = "renesas,ra-cgc-pclk"; /* in zephyr/dts/arm/renesas/ra/ra4/r7fa4e2b93cfm.dtsi:227 */
				div = < 0x2 >;                      /* in zephyr/dts/arm/renesas/ra/ra4/r7fa4e2b93cfm.dtsi:228 */
				#clock-cells = < 0x2 >;             /* in zephyr/dts/arm/renesas/ra/ra4/r7fa4e2b93cfm.dtsi:229 */
				status = "okay";                    /* in zephyr/dts/arm/renesas/ra/ra4/r7fa4e2b93cfm.dtsi:230 */
				phandle = < 0x14 >;                 /* in zephyr/dts/arm/renesas/ra/ra4/ra4-cm33-common.dtsi:140 */
			};

			/* node '/clocks/pclkblock@40084000/pclkb' defined in zephyr/dts/arm/renesas/ra/ra4/r7fa4e2b93cfm.dtsi:233 */
			pclkb: pclkb {
				compatible = "renesas,ra-cgc-pclk"; /* in zephyr/dts/arm/renesas/ra/ra4/r7fa4e2b93cfm.dtsi:234 */
				div = < 0x4 >;                      /* in zephyr/dts/arm/renesas/ra/ra4/r7fa4e2b93cfm.dtsi:235 */
				#clock-cells = < 0x2 >;             /* in zephyr/dts/arm/renesas/ra/ra4/r7fa4e2b93cfm.dtsi:236 */
				status = "okay";                    /* in zephyr/dts/arm/renesas/ra/ra4/r7fa4e2b93cfm.dtsi:237 */
				phandle = < 0x2 >;                  /* in zephyr/dts/arm/renesas/ra/ra4/ra4-cm33-common.dtsi:45 */
			};

			/* node '/clocks/pclkblock@40084000/pclkc' defined in zephyr/dts/arm/renesas/ra/ra4/r7fa4e2b93cfm.dtsi:240 */
			pclkc: pclkc {
				compatible = "renesas,ra-cgc-pclk"; /* in zephyr/dts/arm/renesas/ra/ra4/r7fa4e2b93cfm.dtsi:241 */
				div = < 0x4 >;                      /* in zephyr/dts/arm/renesas/ra/ra4/r7fa4e2b93cfm.dtsi:242 */
				#clock-cells = < 0x2 >;             /* in zephyr/dts/arm/renesas/ra/ra4/r7fa4e2b93cfm.dtsi:243 */
				status = "okay";                    /* in zephyr/dts/arm/renesas/ra/ra4/r7fa4e2b93cfm.dtsi:244 */
			};

			/* node '/clocks/pclkblock@40084000/pclkd' defined in zephyr/dts/arm/renesas/ra/ra4/r7fa4e2b93cfm.dtsi:247 */
			pclkd: pclkd {
				compatible = "renesas,ra-cgc-pclk"; /* in zephyr/dts/arm/renesas/ra/ra4/r7fa4e2b93cfm.dtsi:248 */
				div = < 0x2 >;                      /* in zephyr/dts/arm/renesas/ra/ra4/r7fa4e2b93cfm.dtsi:249 */
				#clock-cells = < 0x2 >;             /* in zephyr/dts/arm/renesas/ra/ra4/r7fa4e2b93cfm.dtsi:250 */
				status = "okay";                    /* in zephyr/dts/arm/renesas/ra/ra4/r7fa4e2b93cfm.dtsi:251 */
				phandle = < 0x1b >;                 /* in zephyr/dts/arm/renesas/ra/ra4/ra4-cm33-common.dtsi:528 */
			};

			/* node '/clocks/pclkblock@40084000/fclk' defined in zephyr/dts/arm/renesas/ra/ra4/r7fa4e2b93cfm.dtsi:254 */
			fclk: fclk {
				compatible = "renesas,ra-cgc-pclk"; /* in zephyr/dts/arm/renesas/ra/ra4/r7fa4e2b93cfm.dtsi:255 */
				div = < 0x4 >;                      /* in zephyr/dts/arm/renesas/ra/ra4/r7fa4e2b93cfm.dtsi:256 */
				#clock-cells = < 0x2 >;             /* in zephyr/dts/arm/renesas/ra/ra4/r7fa4e2b93cfm.dtsi:257 */
				status = "okay";                    /* in zephyr/dts/arm/renesas/ra/ra4/r7fa4e2b93cfm.dtsi:258 */
			};

			/* node '/clocks/pclkblock@40084000/clkout' defined in zephyr/dts/arm/renesas/ra/ra4/r7fa4e2b93cfm.dtsi:261 */
			clkout: clkout {
				compatible = "renesas,ra-cgc-pclk"; /* in zephyr/dts/arm/renesas/ra/ra4/r7fa4e2b93cfm.dtsi:262 */
				#clock-cells = < 0x2 >;             /* in zephyr/dts/arm/renesas/ra/ra4/r7fa4e2b93cfm.dtsi:263 */
				status = "disabled";                /* in zephyr/dts/arm/renesas/ra/ra4/r7fa4e2b93cfm.dtsi:264 */
			};

			/* node '/clocks/pclkblock@40084000/uclk' defined in zephyr/dts/arm/renesas/ra/ra4/r7fa4e2b93cfm.dtsi:267 */
			uclk: uclk {
				compatible = "renesas,ra-cgc-pclk"; /* in zephyr/dts/arm/renesas/ra/ra4/r7fa4e2b93cfm.dtsi:268 */
				#clock-cells = < 0x2 >;             /* in zephyr/dts/arm/renesas/ra/ra4/r7fa4e2b93cfm.dtsi:269 */
				status = "disabled";                /* in zephyr/dts/arm/renesas/ra/ra4/r7fa4e2b93cfm.dtsi:270 */
			};

			/* node '/clocks/pclkblock@40084000/canfdclk' defined in zephyr/dts/arm/renesas/ra/ra4/r7fa4e2b93cfm.dtsi:273 */
			canfdclk: canfdclk {
				compatible = "renesas,ra-cgc-pclk"; /* in zephyr/dts/arm/renesas/ra/ra4/r7fa4e2b93cfm.dtsi:274 */
				#clock-cells = < 0x2 >;             /* in zephyr/dts/arm/renesas/ra/ra4/r7fa4e2b93cfm.dtsi:275 */
				clocks = < &pll >;                  /* in zephyr/boards/renesas/ek_ra4e2/ek_ra4e2.dts:146 */
				div = < 0x8 >;                      /* in zephyr/boards/renesas/ek_ra4e2/ek_ra4e2.dts:147 */
				status = "okay";                    /* in zephyr/boards/renesas/ek_ra4e2/ek_ra4e2.dts:148 */
				phandle = < 0x1d >;                 /* in zephyr/dts/arm/renesas/ra/ra4/r7fa4e2b93cfm.dtsi:84 */
			};

			/* node '/clocks/pclkblock@40084000/i3cclk' defined in zephyr/dts/arm/renesas/ra/ra4/r7fa4e2b93cfm.dtsi:279 */
			i3cclk: i3cclk {
				compatible = "renesas,ra-cgc-pclk"; /* in zephyr/dts/arm/renesas/ra/ra4/r7fa4e2b93cfm.dtsi:280 */
				#clock-cells = < 0x2 >;             /* in zephyr/dts/arm/renesas/ra/ra4/r7fa4e2b93cfm.dtsi:281 */
				clocks = < &pll >;                  /* in zephyr/boards/renesas/ek_ra4e2/ek_ra4e2.dts:152 */
				div = < 0x2 >;                      /* in zephyr/boards/renesas/ek_ra4e2/ek_ra4e2.dts:153 */
				status = "okay";                    /* in zephyr/boards/renesas/ek_ra4e2/ek_ra4e2.dts:154 */
				phandle = < 0x17 >;                 /* in zephyr/dts/arm/renesas/ra/ra4/ra4-cm33-common.dtsi:207 */
			};

			/* node '/clocks/pclkblock@40084000/cecclk' defined in zephyr/dts/arm/renesas/ra/ra4/r7fa4e2b93cfm.dtsi:285 */
			cecclk: cecclk {
				compatible = "renesas,ra-cgc-pclk"; /* in zephyr/dts/arm/renesas/ra/ra4/r7fa4e2b93cfm.dtsi:286 */
				#clock-cells = < 0x2 >;             /* in zephyr/dts/arm/renesas/ra/ra4/r7fa4e2b93cfm.dtsi:287 */
				status = "disabled";                /* in zephyr/dts/arm/renesas/ra/ra4/r7fa4e2b93cfm.dtsi:288 */
			};
		};
	};

	/* node '/leds' defined in zephyr/boards/renesas/ek_ra4e2/ek_ra4e2.dts:29 */
	leds {
		compatible = "gpio-leds"; /* in zephyr/boards/renesas/ek_ra4e2/ek_ra4e2.dts:30 */

		/* node '/leds/led1' defined in zephyr/boards/renesas/ek_ra4e2/ek_ra4e2.dts:32 */
		led1: led1 {
			gpios = < &ioport2 0x7 0x0 >; /* in zephyr/boards/renesas/ek_ra4e2/ek_ra4e2.dts:33 */
			label = "LED1";               /* in zephyr/boards/renesas/ek_ra4e2/ek_ra4e2.dts:34 */
		};

		/* node '/leds/led2' defined in zephyr/boards/renesas/ek_ra4e2/ek_ra4e2.dts:37 */
		led2: led2 {
			gpios = < &ioport1 0x4 0x0 >; /* in zephyr/boards/renesas/ek_ra4e2/ek_ra4e2.dts:38 */
			label = "LED2";               /* in zephyr/boards/renesas/ek_ra4e2/ek_ra4e2.dts:39 */
		};

		/* node '/leds/led3' defined in zephyr/boards/renesas/ek_ra4e2/ek_ra4e2.dts:42 */
		led3: led3 {
			gpios = < &ioport1 0xc 0x0 >; /* in zephyr/boards/renesas/ek_ra4e2/ek_ra4e2.dts:43 */
			label = "LED3";               /* in zephyr/boards/renesas/ek_ra4e2/ek_ra4e2.dts:44 */
		};
	};

	/* node '/buttons' defined in zephyr/boards/renesas/ek_ra4e2/ek_ra4e2.dts:48 */
	buttons {
		compatible = "gpio-keys"; /* in zephyr/boards/renesas/ek_ra4e2/ek_ra4e2.dts:49 */

		/* node '/buttons/s1' defined in zephyr/boards/renesas/ek_ra4e2/ek_ra4e2.dts:51 */
		button0: s1 {
			gpios = < &ioport0 0x5 0x11 >;  /* in zephyr/boards/renesas/ek_ra4e2/ek_ra4e2.dts:52 */
			label = "Push button switch 1"; /* in zephyr/boards/renesas/ek_ra4e2/ek_ra4e2.dts:53 */
			zephyr,code = < 0xb >;          /* in zephyr/boards/renesas/ek_ra4e2/ek_ra4e2.dts:54 */
		};

		/* node '/buttons/s2' defined in zephyr/boards/renesas/ek_ra4e2/ek_ra4e2.dts:57 */
		button1: s2 {
			gpios = < &ioport3 0x4 0x11 >;  /* in zephyr/boards/renesas/ek_ra4e2/ek_ra4e2.dts:58 */
			label = "Push button switch 2"; /* in zephyr/boards/renesas/ek_ra4e2/ek_ra4e2.dts:59 */
			zephyr,code = < 0x2 >;          /* in zephyr/boards/renesas/ek_ra4e2/ek_ra4e2.dts:60 */
		};
	};

	/* node '/can-phy0' defined in zephyr/boards/renesas/ek_ra4e2/ek_ra4e2.dts:71 */
	transceiver0: can-phy0 {
		compatible = "nxp,tja1043t",
		             "can-transceiver-gpio";  /* in zephyr/boards/renesas/ek_ra4e2/ek_ra4e2.dts:72 */
		standby-gpios = < &ioport4 0x0 0x1 >; /* in zephyr/boards/renesas/ek_ra4e2/ek_ra4e2.dts:73 */
		max-bitrate = < 0x4c4b40 >;           /* in zephyr/boards/renesas/ek_ra4e2/ek_ra4e2.dts:74 */
		#phy-cells = < 0x0 >;                 /* in zephyr/boards/renesas/ek_ra4e2/ek_ra4e2.dts:75 */
		phandle = < 0x1f >;                   /* in zephyr/boards/renesas/ek_ra4e2/ek_ra4e2.dts:163 */
	};

	/* node '/zephyr,user' defined in zephyr/boards/renesas/ek_ra4e2/ek_ra4e2.dts:78 */
	zephyr,user {
		i3c-pullup-gpios = < &ioport2 0x5 0x1 >,
		                   < &ioport2 0x6 0x1 >; /* in zephyr/boards/renesas/ek_ra4e2/ek_ra4e2.dts:79 */
	};
};
